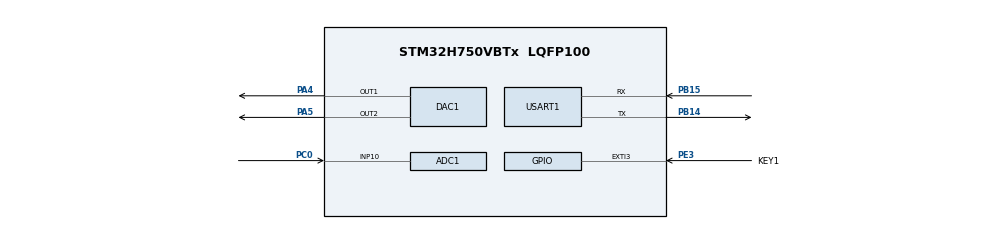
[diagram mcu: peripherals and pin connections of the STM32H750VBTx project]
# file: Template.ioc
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ADC1.Channel-0\#ChannelRegularConversion=ADC_CHANNEL_10
ADC1.ConversionDataManagement=ADC_CONVERSIONDATA_DMA_CIRCULAR
ADC1.ExternalTrigConv=ADC_EXTERNALTRIG_T15_TRGO
ADC1.NbrOfConversionFlag=1
ADC1.OffsetNumber-0\#ChannelRegularConversion=ADC_OFFSET_NONE
ADC1.OffsetSignedSaturation-0\#ChannelRegularConversion=DISABLE
ADC1.Rank-0\#ChannelRegularConversion=1
ADC1.SamplingTime-0\#ChannelRegularConversion=ADC_SAMPLETIME_1CYCLE_5
ADC1.master=1
CORTEX_M7.AccessPermission-Cortex_Memory_Protection_Unit_Region0_Settings=MPU_REGION_FULL_ACCESS
CORTEX_M7.AccessPermission-Cortex_Memory_Protection_Unit_Region1_Settings=MPU_REGION_FULL_ACCESS
CORTEX_M7.AccessPermission-Cortex_Memory_Protection_Unit_Region2_Settings=MPU_REGION_FULL_ACCESS
CORTEX_M7.AccessPermission-Cortex_Memory_Protection_Unit_Region3_Settings=MPU_REGION_FULL_ACCESS
CORTEX_M7.AccessPermission-Cortex_Memory_Protection_Unit_Region4_Settings=MPU_REGION_FULL_ACCESS
CORTEX_M7.BaseAddress-Cortex_Memory_Protection_Unit_Region0_Settings=0x24000000
CORTEX_M7.BaseAddress-Cortex_Memory_Protection_Unit_Region1_Settings=0x30000000
CORTEX_M7.BaseAddress-Cortex_Memory_Protection_Unit_Region2_Settings=0x30020000
CORTEX_M7.BaseAddress-Cortex_Memory_Protection_Unit_Region3_Settings=0x30040000
CORTEX_M7.BaseAddress-Cortex_Memory_Protection_Unit_Region4_Settings=0x38000000
CORTEX_M7.CPU_DCache=Enabled
CORTEX_M7.CPU_ICache=Enabled
CORTEX_M7.Enable-Cortex_Memory_Protection_Unit_Region0_Settings=MPU_REGION_ENABLE
CORTEX_M7.Enable-Cortex_Memory_Protection_Unit_Region1_Settings=MPU_REGION_ENABLE
CORTEX_M7.Enable-Cortex_Memory_Protection_Unit_Region2_Settings=MPU_REGION_ENABLE
CORTEX_M7.Enable-Cortex_Memory_Protection_Unit_Region3_Settings=MPU_REGION_ENABLE
CORTEX_M7.Enable-Cortex_Memory_Protection_Unit_Region4_Settings=MPU_REGION_ENABLE
CORTEX_M7.IsBufferable-Cortex_Memory_Protection_Unit_Region0_Settings=MPU_ACCESS_BUFFERABLE
CORTEX_M7.IsCacheable-Cortex_Memory_Protection_Unit_Region0_Settings=MPU_ACCESS_CACHEABLE
CORTEX_M7.MPU_Control=MPU_PRIVILEGED_DEFAULT
CORTEX_M7.Size-Cortex_Memory_Protection_Unit_Region0_Settings=MPU_REGION_SIZE_512KB
CORTEX_M7.Size-Cortex_Memory_Protection_Unit_Region1_Settings=MPU_REGION_SIZE_128KB
CORTEX_M7.Size-Cortex_Memory_Protection_Unit_Region2_Settings=MPU_REGION_SIZE_128KB
CORTEX_M7.Size-Cortex_Memory_Protection_Unit_Region3_Settings=MPU_REGION_SIZE_32KB
CORTEX_M7.Size-Cortex_Memory_Protection_Unit_Region4_Settings=MPU_REGION_SIZE_64KB
CORTEX_M7.TypeExtField-Cortex_Memory_Protection_Unit_Region0_Settings=MPU_TEX_LEVEL1
CORTEX_M7.TypeExtField-Cortex_Memory_Protection_Unit_Region1_Settings=MPU_TEX_LEVEL1
CORTEX_M7.TypeExtField-Cortex_Memory_Protection_Unit_Region2_Settings=MPU_TEX_LEVEL1
CORTEX_M7.TypeExtField-Cortex_Memory_Protection_Unit_Region3_Settings=MPU_TEX_LEVEL1
CORTEX_M7.TypeExtField-Cortex_Memory_Protection_Unit_Region4_Settings=MPU_TEX_LEVEL1
DAC1.DAC1_OutputBuffer-DAC_OUT1=DAC_OUTPUTBUFFER_DISABLE
DAC1.DAC2_OutputBuffer-DAC_OUT2=DAC_OUTPUTBUFFER_DISABLE
DAC1.DAC_Channel-DAC_OUT1=DAC_CHANNEL_1
DAC1.DAC_Channel-DAC_OUT2=DAC_CHANNEL_2
DAC1.DAC_Trigger-DAC_OUT1=DAC_TRIGGER_T1_TRGO
DAC1.DAC_Trigger-DAC_OUT2=DAC_TRIGGER_T4_TRGO
DAC1.DAC_UserTrimming-DAC_OUT1=DAC_TRIMMING_FACTORY
Dma.ADC1.0.Direction=DMA_PERIPH_TO_MEMORY
Dma.ADC1.0.EventEnable=DISABLE
Dma.ADC1.0.FIFOMode=DMA_FIFOMODE_DISABLE
Dma.ADC1.0.Instance=DMA1_Stream0
Dma.ADC1.0.MemDataAlignment=DMA_MDATAALIGN_HALFWORD
Dma.ADC1.0.MemInc=DMA_MINC_ENABLE
Dma.ADC1.0.Mode=DMA_NORMAL
Dma.ADC1.0.PeriphDataAlignment=DMA_PDATAALIGN_HALFWORD
Dma.ADC1.0.PeriphInc=DMA_PINC_DISABLE
Dma.ADC1.0.Polarity=HAL_DMAMUX_REQ_GEN_RISING
Dma.ADC1.0.Priority=DMA_PRIORITY_LOW
Dma.ADC1.0.RequestNumber=1
Dma.ADC1.0.SignalID=NONE
Dma.ADC1.0.SyncEnable=DISABLE
Dma.ADC1.0.SyncPolarity=HAL_DMAMUX_SYNC_NO_EVENT
Dma.ADC1.0.SyncRequestNumber=1
Dma.ADC1.0.SyncSignalID=NONE
Dma.DAC1_CH1.1.Direction=DMA_MEMORY_TO_PERIPH
Dma.DAC1_CH1.1.EventEnable=DISABLE
Dma.DAC1_CH1.1.FIFOMode=DMA_FIFOMODE_DISABLE
Dma.DAC1_CH1.1.Instance=DMA1_Stream1
Dma.DAC1_CH1.1.MemDataAlignment=DMA_MDATAALIGN_HALFWORD
Dma.DAC1_CH1.1.MemInc=DMA_MINC_ENABLE
Dma.DAC1_CH1.1.Mode=DMA_CIRCULAR
Dma.DAC1_CH1.1.PeriphDataAlignment=DMA_PDATAALIGN_HALFWORD
Dma.DAC1_CH1.1.PeriphInc=DMA_PINC_DISABLE
Dma.DAC1_CH1.1.Polarity=HAL_DMAMUX_REQ_GEN_RISING
Dma.DAC1_CH1.1.Priority=DMA_PRIORITY_LOW
Dma.DAC1_CH1.1.RequestNumber=1
Dma.DAC1_CH1.1.SignalID=NONE
Dma.DAC1_CH1.1.SyncEnable=DISABLE
Dma.DAC1_CH1.1.SyncPolarity=HAL_DMAMUX_SYNC_NO_EVENT
Dma.DAC1_CH1.1.SyncRequestNumber=1
Dma.DAC1_CH1.1.SyncSignalID=NONE
Dma.DAC1_CH2.2.Direction=DMA_MEMORY_TO_PERIPH
Dma.DAC1_CH2.2.EventEnable=DISABLE
Dma.DAC1_CH2.2.FIFOMode=DMA_FIFOMODE_DISABLE
Dma.DAC1_CH2.2.Instance=DMA1_Stream2
Dma.DAC1_CH2.2.MemDataAlignment=DMA_MDATAALIGN_HALFWORD
Dma.DAC1_CH2.2.MemInc=DMA_MINC_ENABLE
Dma.DAC1_CH2.2.Mode=DMA_CIRCULAR
Dma.DAC1_CH2.2.PeriphDataAlignment=DMA_PDATAALIGN_HALFWORD
Dma.DAC1_CH2.2.PeriphInc=DMA_PINC_DISABLE
Dma.DAC1_CH2.2.Polarity=HAL_DMAMUX_REQ_GEN_RISING
Dma.DAC1_CH2.2.Priority=DMA_PRIORITY_LOW
Dma.DAC1_CH2.2.RequestNumber=1
Dma.DAC1_CH2.2.SignalID=NONE
Dma.DAC1_CH2.2.SyncEnable=DISABLE
Dma.DAC1_CH2.2.SyncPolarity=HAL_DMAMUX_SYNC_NO_EVENT
Dma.DAC1_CH2.2.SyncRequestNumber=1
Dma.DAC1_CH2.2.SyncSignalID=NONE
Dma.Request0=ADC1
Dma.Request1=DAC1_CH1
Dma.Request2=DAC1_CH2
Mcu.Family=STM32H7
Mcu.Name=STM32H750VBTx
Mcu.Package=LQFP100
NVIC.DMA1_Stream0_IRQn=true\:0\:0\:false\:false\:true\:false\:true\:true
NVIC.DMA1_Stream1_IRQn=true\:0\:0\:false\:false\:true\:false\:true\:true
NVIC.DMA1_Stream2_IRQn=true\:0\:0\:false\:false\:true\:false\:true\:true
NVIC.EXTI3_IRQn=true\:0\:0\:false\:false\:true\:true\:true\:true
NVIC.PriorityGroup=NVIC_PRIORITYGROUP_4
PA13\ (JTMS/SWDIO).Mode=Serial_Wire
PA13\ (JTMS/SWDIO).Signal=DEBUG_JTMS-SWDIO
PA14\ (JTCK/SWCLK).Mode=Serial_Wire
PA14\ (JTCK/SWCLK).Signal=DEBUG_JTCK-SWCLK
PA4.Signal=COMP_DAC11_group
PA5.Signal=COMP_DAC12_group
PB14.Mode=Asynchronous
PB14.Signal=USART1_TX
PB15.Mode=Asynchronous
PB15.Signal=USART1_RX
PC0.Signal=ADCx_INP10
PE3.GPIO_Label=KEY1
PE3.GPIO_ModeDefaultEXTI=GPIO_MODE_IT_FALLING
PE3.GPIO_PuPd=GPIO_PULLUP
PE3.Signal=GPXTI3
PH0-OSC_IN\ (PH0).Mode=HSE-External-Oscillator
PH0-OSC_IN\ (PH0).Signal=RCC_OSC_IN
PH1-OSC_OUT\ (PH1).Mode=HSE-External-Oscillator
PH1-OSC_OUT\ (PH1).Signal=RCC_OSC_OUT
ProjectManager.HeapSize=0x200
ProjectManager.StackSize=0x7400
ProjectManager.TargetToolchain=MDK-ARM V5.32
RCC.ADCFreq_Value=72000000
RCC.APB1Freq_Value=120000000
RCC.APB2Freq_Value=120000000
RCC.APB3Freq_Value=120000000
RCC.APB4Freq_Value=120000000
RCC.CortexFreq_Value=480000000
RCC.D1PPRE=RCC_APB3_DIV2
RCC.D2PPRE1=RCC_APB1_DIV2
RCC.D2PPRE2=RCC_APB2_DIV2
RCC.D3PPRE=RCC_APB4_DIV2
RCC.DIVM1=5
RCC.DIVM2=25
RCC.DIVN1=192
RCC.DIVN2=360
RCC.DIVP2=5
RCC.HCLKFreq_Value=240000000
RCC.HPRE=RCC_HCLK_DIV2
RCC.PLLSourceVirtual=RCC_PLLSOURCE_HSE
RCC.ProductRev=revV
RCC.SYSCLKFreq_VALUE=480000000
RCC.SYSCLKSource=RCC_SYSCLKSOURCE_PLLCLK
RCC.USBFreq_Value=480000000
SH.ADCx_INP10.0=ADC1_INP10,IN10-Single-Ended
SH.COMP_DAC11_group.0=DAC1_OUT1,DAC_OUT1
SH.COMP_DAC12_group.0=DAC1_OUT2,DAC_OUT2
TIM1.Period=240-1
TIM1.TIM_MasterOutputTrigger=TIM_TRGO_UPDATE
TIM15.Period=240-1
TIM15.TIM_MasterOutputTrigger=TIM_TRGO_UPDATE
TIM4.AutoReloadPreload=TIM_AUTORELOAD_PRELOAD_ENABLE
TIM4.Period=240-1
TIM4.TIM_MasterOutputTrigger=TIM_TRGO_UPDATE
TIM7.Prescaler=239
USART1.VirtualMode-Asynchronous=VM_ASYNC
VP_TIM15_VS_ClockSourceINT.Mode=Internal
VP_TIM1_VS_ClockSourceINT.Mode=Internal
VP_TIM4_VS_ClockSourceINT.Mode=Internal
VP_TIM7_VS_ClockSourceINT.Mode=Enable_Timer
board=custom

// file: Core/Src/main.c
/* USER CODE BEGIN Header */
/**
  ******************************************************************************
  * @file           : main.c
  * @brief          : Main program body
  ******************************************************************************
  * @attention
  *
  * Copyright (c) 2023 STMicroelectronics.
  * All rights reserved.
  *
  * This software is licensed under terms that can be found in the LICENSE file
  * in the root directory of this software component.
  * If no LICENSE file comes with this software, it is provided AS-IS.
  *
  ******************************************************************************
  */
/* USER CODE END Header */
#include "main.h"
#include "adc.h"
#include "dac.h"
#include "dma.h"
#include "tim.h"
#include "usart.h"
#include "gpio.h"

/* USER CODE BEGIN PTD */
ALIGN_32BYTES (uint16_t adc1_data[DFT_LENGTH]) 	__attribute__((section(".ARM.__at_0x30000000")));
__IO uint8_t AdcConvEnd = 0;//表示adc采集完成

uint8_t mode_flag = 0;			//0自校正，1手调节
uint8_t restart_flag = 0;		//重新分离

// 信号频率	索引
uint8_t fre[2];
// 信号种类	0正弦 1三角
uint8_t wave_type[2];
//	DAC输出数据
ALIGN_32BYTES (uint16_t data_A[200]) 	__attribute__((section(".ARM.__at_0x38000000")));
ALIGN_32BYTES (uint16_t data_B[200]) 	__attribute__((section(".ARM.__at_0x38004000")));
//	信号相差
double pos_angle_A;
double pos_angle_B;
//时差
double delayA;
//	延时
uint32_t delayT_A;
uint32_t delayT_B;
//	输入移相0-180
uint8_t change_pha = 0;
/* USER CODE END PTD */

/* USER CODE BEGIN PM */

// 标准频率sin与cos表
uint16_t DAC_SIN[200 * 19] =
    // 第一行是20K -> 1s 10K
    { // DAC正弦缓冲区,每行 200点。第一行有2个正弦波，第三行有4个……第19行有20个
        2142, 2236, 2329, 2421, 2512, 2600, 2687, 2771, 2852, 2930, 3004, 3075, 3141, 3204, 3262, 3314, 3362, 3405, 3443, 3475, 3501, 3521, 3536, 3545, 3548, 3545, 3536, 3521, 3501, 3475, 3443, 3405, 3362, 3314, 3262, 3204, 3141, 3075, 3004, 2930, 2852, 2771, 2687, 2600, 2512, 2421, 2329, 2236, 2142, 2048, 1954, 1860, 1767, 1675, 1584, 1496, 1409, 1325, 1244, 1166, 1092, 1021, 955, 892, 834, 782, 734, 691, 653, 621, 595, 575, 560, 551, 548, 551, 560, 575, 595, 621, 653, 691, 734, 782, 834, 892, 955, 1021, 1092, 1166, 1244, 1325, 1409, 1496, 1584, 1675, 1767, 1860, 1954, 2048, 2142, 2236, 2329, 2421, 2512, 2600, 2687, 2771, 2852, 2930, 3004, 3075, 3141, 3204, 3262, 3314, 3362, 3405, 3443, 3475, 3501, 3521, 3536, 3545, 3548, 3545, 3536, 3521, 3501, 3475, 3443, 3405, 3362, 3314, 3262, 3204, 3141, 3075, 3004, 2930, 2852, 2771, 2687, 2600, 2512, 2421, 2329, 2236, 2142, 2048, 1954, 1860, 1767, 1675, 1584, 1496, 1409, 1325, 1244, 1166, 1092, 1021, 955, 892, 834, 782, 734, 691, 653, 621, 595, 575, 560, 551, 548, 551, 560, 575, 595, 621, 653, 691, 734, 782, 834, 892, 955, 1021, 1092, 1166, 1244, 1325, 1409, 1496, 1584, 1675, 1767, 1860, 1954, 2048,
        2189, 2329, 2466, 2600, 2729, 2852, 2967, 3075, 3173, 3262, 3339, 3405, 3459, 3501, 3530, 3545, 3547, 3536, 3512, 3475, 3425, 3362, 3289, 3204, 3109, 3004, 2891, 2771, 2644, 2512, 2375, 2236, 2095, 1954, 1813, 1675, 1540, 1409, 1284, 1166, 1056, 955, 863, 782, 711, 653, 608, 575, 555, 548, 555, 575, 608, 653, 711, 782, 863, 955, 1056, 1166, 1284, 1409, 1540, 1675, 1813, 1954, 2095, 2236, 2375, 2512, 2644, 2771, 2891, 3004, 3109, 3204, 3289, 3362, 3425, 3475, 3512, 3536, 3547, 3545, 3530, 3501, 3459, 3405, 3339, 3262, 3173, 3075, 2967, 2852, 2729, 2600, 2466, 2329, 2189, 2048, 1907, 1767, 1630, 1496, 1367, 1244, 1129, 1021, 923, 834, 757, 691, 637, 595, 566, 551, 549, 560, 584, 621, 671, 734, 807, 892, 987, 1092, 1205, 1325, 1452, 1584, 1721, 1860, 2001, 2142, 2283, 2421, 2556, 2687, 2812, 2930, 3040, 3141, 3233, 3314, 3385, 3443, 3488, 3521, 3541, 3548, 3541, 3521, 3488, 3443, 3385, 3314, 3233, 3141, 3040, 2930, 2812, 2687, 2556, 2421, 2283, 2142, 2001, 1860, 1721, 1584, 1452, 1325, 1205, 1092, 987, 892, 807, 734, 671, 621, 584, 560, 549, 551, 566, 595, 637, 691, 757, 834, 923, 1021, 1129, 1244, 1367, 1496, 1630, 1767, 1907, 2048,
        2236, 2421, 2600, 2771, 2930, 3075, 3204, 3314, 3405, 3475, 3521, 3545, 3545, 3521, 3475, 3405, 3314, 3204, 3075, 2930, 2771, 2600, 2421, 2236, 2048, 1860, 1675, 1496, 1325, 1166, 1021, 892, 782, 691, 621, 575, 551, 551, 575, 621, 691, 782, 892, 1021, 1166, 1325, 1496, 1675, 1860, 2048, 2236, 2421, 2600, 2771, 2930, 3075, 3204, 3314, 3405, 3475, 3521, 3545, 3545, 3521, 3475, 3405, 3314, 3204, 3075, 2930, 2771, 2600, 2421, 2236, 2048, 1860, 1675, 1496, 1325, 1166, 1021, 892, 782, 691, 621, 575, 551, 551, 575, 621, 691, 782, 892, 1021, 1166, 1325, 1496, 1675, 1860, 2048, 2236, 2421, 2600, 2771, 2930, 3075, 3204, 3314, 3405, 3475, 3521, 3545, 3545, 3521, 3475, 3405, 3314, 3204, 3075, 2930, 2771, 2600, 2421, 2236, 2048, 1860, 1675, 1496, 1325, 1166, 1021, 892, 782, 691, 621, 575, 551, 551, 575, 621, 691, 782, 892, 1021, 1166, 1325, 1496, 1675, 1860, 2048, 2236, 2421, 2600, 2771, 2930, 3075, 3204, 3314, 3405, 3475, 3521, 3545, 3545, 3521, 3475, 3405, 3314, 3204, 3075, 2930, 2771, 2600, 2421, 2236, 2048, 1860, 1675, 1496, 1325, 1166, 1021, 892, 782, 691, 621, 575, 551, 551, 575, 621, 691, 782, 892, 1021, 1166, 1325, 1496, 1675, 1860, 2048,
        2283, 2512, 2729, 2930, 3109, 3262, 3385, 3475, 3530, 3548, 3530, 3475, 3385, 3262, 3109, 2930, 2729, 2512, 2283, 2048, 1813, 1584, 1367, 1166, 987, 834, 711, 621, 566, 548, 566, 621, 711, 834, 987, 1166, 1367, 1584, 1813, 2048, 2283, 2512, 2729, 2930, 3109, 3262, 3385, 3475, 3530, 3548, 3530, 3475, 3385, 3262, 3109, 2930, 2729, 2512, 2283, 2048, 1813, 1584, 1367, 1166, 987, 834, 711, 621, 566, 548, 566, 621, 711, 834, 987, 1166, 1367, 1584, 1813, 2048, 2283, 2512, 2729, 2930, 3109, 3262, 3385, 3475, 3530, 3548, 3530, 3475, 3385, 3262, 3109, 2930, 2729, 2512, 2283, 2048, 1813, 1584, 1367, 1166, 987, 834, 711, 621, 566, 548, 566, 621, 711, 834, 987, 1166, 1367, 1584, 1813, 2048, 2283, 2512, 2729, 2930, 3109, 3262, 3385, 3475, 3530, 3548, 3530, 3475, 3385, 3262, 3109, 2930, 2729, 2512, 2283, 2048, 1813, 1584, 1367, 1166, 987, 834, 711, 621, 566, 548, 566, 621, 711, 834, 987, 1166, 1367, 1584, 1813, 2048, 2283, 2512, 2729, 2930, 3109, 3262, 3385, 3475, 3530, 3548, 3530, 3475, 3385, 3262, 3109, 2930, 2729, 2512, 2283, 2048, 1813, 1584, 1367, 1166, 987, 834, 711, 621, 566, 548, 566, 621, 711, 834, 987, 1166, 1367, 1584, 1813, 2048,
        2329, 2600, 2852, 3075, 3262, 3405, 3501, 3545, 3536, 3475, 3362, 3204, 3004, 2771, 2512, 2236, 1954, 1675, 1409, 1166, 955, 782, 653, 575, 548, 575, 653, 782, 955, 1166, 1409, 1675, 1954, 2236, 2512, 2771, 3004, 3204, 3362, 3475, 3536, 3545, 3501, 3405, 3262, 3075, 2852, 2600, 2329, 2048, 1767, 1496, 1244, 1021, 834, 691, 595, 551, 560, 621, 734, 892, 1092, 1325, 1584, 1860, 2142, 2421, 2687, 2930, 3141, 3314, 3443, 3521, 3548, 3521, 3443, 3314, 3141, 2930, 2687, 2421, 2142, 1860, 1584, 1325, 1092, 892, 734, 621, 560, 551, 595, 691, 834, 1021, 1244, 1496, 1767, 2048, 2329, 2600, 2852, 3075, 3262, 3405, 3501, 3545, 3536, 3475, 3362, 3204, 3004, 2771, 2512, 2236, 1954, 1675, 1409, 1166, 955, 782, 653, 575, 548, 575, 653, 782, 955, 1166, 1409, 1675, 1954, 2236, 2512, 2771, 3004, 3204, 3362, 3475, 3536, 3545, 3501, 3405, 3262, 3075, 2852, 2600, 2329, 2048, 1767, 1496, 1244, 1021, 834, 691, 595, 551, 560, 621, 734, 892, 1092, 1325, 1584, 1860, 2142, 2421, 2687, 2930, 3141, 3314, 3443, 3521, 3548, 3521, 3443, 3314, 3141, 2930, 2687, 2421, 2142, 1860, 1584, 1325, 1092, 892, 734, 621, 560, 551, 595, 691, 834, 1021, 1244, 1496, 1767, 2048,
        2375, 2687, 2967, 3204, 3385, 3501, 3547, 3521, 3425, 3262, 3040, 2771, 2466, 2142, 1813, 1496, 1205, 955, 757, 621, 555, 560, 637, 782, 987, 1244, 1540, 1860, 2189, 2512, 2812, 3075, 3289, 3443, 3530, 3545, 3488, 3362, 3173, 2930, 2644, 2329, 2001, 1675, 1367, 1092, 863, 691, 584, 548, 584, 691, 863, 1092, 1367, 1675, 2001, 2329, 2644, 2930, 3173, 3362, 3488, 3545, 3530, 3443, 3289, 3075, 2812, 2512, 2189, 1860, 1540, 1244, 987, 782, 637, 560, 555, 621, 757, 955, 1205, 1496, 1813, 2142, 2466, 2771, 3040, 3262, 3425, 3521, 3547, 3501, 3385, 3204, 2967, 2687, 2375, 2048, 1721, 1409, 1129, 892, 711, 595, 549, 575, 671, 834, 1056, 1325, 1630, 1954, 2283, 2600, 2891, 3141, 3339, 3475, 3541, 3536, 3459, 3314, 3109, 2852, 2556, 2236, 1907, 1584, 1284, 1021, 807, 653, 566, 551, 608, 734, 923, 1166, 1452, 1767, 2095, 2421, 2729, 3004, 3233, 3405, 3512, 3548, 3512, 3405, 3233, 3004, 2729, 2421, 2095, 1767, 1452, 1166, 923, 734, 608, 551, 566, 653, 807, 1021, 1284, 1584, 1907, 2236, 2556, 2852, 3109, 3314, 3459, 3536, 3541, 3475, 3339, 3141, 2891, 2600, 2283, 1954, 1630, 1325, 1056, 834, 671, 575, 549, 595, 711, 892, 1129, 1409, 1721, 2048,
        2421, 2771, 3075, 3314, 3475, 3545, 3521, 3405, 3204, 2930, 2600, 2236, 1860, 1496, 1166, 892, 691, 575, 551, 621, 782, 1021, 1325, 1675, 2048, 2421, 2771, 3075, 3314, 3475, 3545, 3521, 3405, 3204, 2930, 2600, 2236, 1860, 1496, 1166, 892, 691, 575, 551, 621, 782, 1021, 1325, 1675, 2048, 2421, 2771, 3075, 3314, 3475, 3545, 3521, 3405, 3204, 2930, 2600, 2236, 1860, 1496, 1166, 892, 691, 575, 551, 621, 782, 1021, 1325, 1675, 2048, 2421, 2771, 3075, 3314, 3475, 3545, 3521, 3405, 3204, 2930, 2600, 2236, 1860, 1496, 1166, 892, 691, 575, 551, 621, 782, 1021, 1325, 1675, 2048, 2421, 2771, 3075, 3314, 3475, 3545, 3521, 3405, 3204, 2930, 2600, 2236, 1860, 1496, 1166, 892, 691, 575, 551, 621, 782, 1021, 1325, 1675, 2048, 2421, 2771, 3075, 3314, 3475, 3545, 3521, 3405, 3204, 2930, 2600, 2236, 1860, 1496, 1166, 892, 691, 575, 551, 621, 782, 1021, 1325, 1675, 2048, 2421, 2771, 3075, 3314, 3475, 3545, 3521, 3405, 3204, 2930, 2600, 2236, 1860, 1496, 1166, 892, 691, 575, 551, 621, 782, 1021, 1325, 1675, 2048, 2421, 2771, 3075, 3314, 3475, 3545, 3521, 3405, 3204, 2930, 2600, 2236, 1860, 1496, 1166, 892, 691, 575, 551, 621, 782, 1021, 1325, 1675, 2048,
        2466, 2852, 3173, 3405, 3530, 3536, 3425, 3204, 2891, 2512, 2095, 1675, 1284, 955, 711, 575, 555, 653, 863, 1166, 1540, 1954, 2375, 2771, 3109, 3362, 3512, 3545, 3459, 3262, 2967, 2600, 2189, 1767, 1367, 1021, 757, 595, 549, 621, 807, 1092, 1452, 1860, 2283, 2687, 3040, 3314, 3488, 3548, 3488, 3314, 3040, 2687, 2283, 1860, 1452, 1092, 807, 621, 549, 595, 757, 1021, 1367, 1767, 2189, 2600, 2967, 3262, 3459, 3545, 3512, 3362, 3109, 2771, 2375, 1954, 1540, 1166, 863, 653, 555, 575, 711, 955, 1284, 1675, 2095, 2512, 2891, 3204, 3425, 3536, 3530, 3405, 3173, 2852, 2466, 2048, 1630, 1244, 923, 691, 566, 560, 671, 892, 1205, 1584, 2001, 2421, 2812, 3141, 3385, 3521, 3541, 3443, 3233, 2930, 2556, 2142, 1721, 1325, 987, 734, 584, 551, 637, 834, 1129, 1496, 1907, 2329, 2729, 3075, 3339, 3501, 3547, 3475, 3289, 3004, 2644, 2236, 1813, 1409, 1056, 782, 608, 548, 608, 782, 1056, 1409, 1813, 2236, 2644, 3004, 3289, 3475, 3547, 3501, 3339, 3075, 2729, 2329, 1907, 1496, 1129, 834, 637, 551, 584, 734, 987, 1325, 1721, 2142, 2556, 2930, 3233, 3443, 3541, 3521, 3385, 3141, 2812, 2421, 2001, 1584, 1205, 892, 671, 560, 566, 691, 923, 1244, 1630, 2048,
        2512, 2930, 3262, 3475, 3548, 3475, 3262, 2930, 2512, 2048, 1584, 1166, 834, 621, 548, 621, 834, 1166, 1584, 2048, 2512, 2930, 3262, 3475, 3548, 3475, 3262, 2930, 2512, 2048, 1584, 1166, 834, 621, 548, 621, 834, 1166, 1584, 2048, 2512, 2930, 3262, 3475, 3548, 3475, 3262, 2930, 2512, 2048, 1584, 1166, 834, 621, 548, 621, 834, 1166, 1584, 2048, 2512, 2930, 3262, 3475, 3548, 3475, 3262, 2930, 2512, 2048, 1584, 1166, 834, 621, 548, 621, 834, 1166, 1584, 2048, 2512, 2930, 3262, 3475, 3548, 3475, 3262, 2930, 2512, 2048, 1584, 1166, 834, 621, 548, 621, 834, 1166, 1584, 2048, 2512, 2930, 3262, 3475, 3548, 3475, 3262, 2930, 2512, 2048, 1584, 1166, 834, 621, 548, 621, 834, 1166, 1584, 2048, 2512, 2930, 3262, 3475, 3548, 3475, 3262, 2930, 2512, 2048, 1584, 1166, 834, 621, 548, 621, 834, 1166, 1584, 2048, 2512, 2930, 3262, 3475, 3548, 3475, 3262, 2930, 2512, 2048, 1584, 1166, 834, 621, 548, 621, 834, 1166, 1584, 2048, 2512, 2930, 3262, 3475, 3548, 3475, 3262, 2930, 2512, 2048, 1584, 1166, 834, 621, 548, 621, 834, 1166, 1584, 2048, 2512, 2930, 3262, 3475, 3548, 3475, 3262, 2930, 2512, 2048, 1584, 1166, 834, 621, 548, 621, 834, 1166, 1584, 2048,
        2556, 3004, 3339, 3521, 3530, 3362, 3040, 2600, 2095, 1584, 1129, 782, 584, 560, 711, 1021, 1452, 1954, 2466, 2930, 3289, 3501, 3541, 3405, 3109, 2687, 2189, 1675, 1205, 834, 608, 551, 671, 955, 1367, 1860, 2375, 2852, 3233, 3475, 3547, 3443, 3173, 2771, 2283, 1767, 1284, 892, 637, 548, 637, 892, 1284, 1767, 2283, 2771, 3173, 3443, 3547, 3475, 3233, 2852, 2375, 1860, 1367, 955, 671, 551, 608, 834, 1205, 1675, 2189, 2687, 3109, 3405, 3541, 3501, 3289, 2930, 2466, 1954, 1452, 1021, 711, 560, 584, 782, 1129, 1584, 2095, 2600, 3040, 3362, 3530, 3521, 3339, 3004, 2556, 2048, 1540, 1092, 757, 575, 566, 734, 1056, 1496, 2001, 2512, 2967, 3314, 3512, 3536, 3385, 3075, 2644, 2142, 1630, 1166, 807, 595, 555, 691, 987, 1409, 1907, 2421, 2891, 3262, 3488, 3545, 3425, 3141, 2729, 2236, 1721, 1244, 863, 621, 549, 653, 923, 1325, 1813, 2329, 2812, 3204, 3459, 3548, 3459, 3204, 2812, 2329, 1813, 1325, 923, 653, 549, 621, 863, 1244, 1721, 2236, 2729, 3141, 3425, 3545, 3488, 3262, 2891, 2421, 1907, 1409, 987, 691, 555, 595, 807, 1166, 1630, 2142, 2644, 3075, 3385, 3536, 3512, 3314, 2967, 2512, 2001, 1496, 1056, 734, 566, 575, 757, 1092, 1540, 2048,
        2600, 3075, 3405, 3545, 3475, 3204, 2771, 2236, 1675, 1166, 782, 575, 575, 782, 1166, 1675, 2236, 2771, 3204, 3475, 3545, 3405, 3075, 2600, 2048, 1496, 1021, 691, 551, 621, 892, 1325, 1860, 2421, 2930, 3314, 3521, 3521, 3314, 2930, 2421, 1860, 1325, 892, 621, 551, 691, 1021, 1496, 2048, 2600, 3075, 3405, 3545, 3475, 3204, 2771, 2236, 1675, 1166, 782, 575, 575, 782, 1166, 1675, 2236, 2771, 3204, 3475, 3545, 3405, 3075, 2600, 2048, 1496, 1021, 691, 551, 621, 892, 1325, 1860, 2421, 2930, 3314, 3521, 3521, 3314, 2930, 2421, 1860, 1325, 892, 621, 551, 691, 1021, 1496, 2048, 2600, 3075, 3405, 3545, 3475, 3204, 2771, 2236, 1675, 1166, 782, 575, 575, 782, 1166, 1675, 2236, 2771, 3204, 3475, 3545, 3405, 3075, 2600, 2048, 1496, 1021, 691, 551, 621, 892, 1325, 1860, 2421, 2930, 3314, 3521, 3521, 3314, 2930, 2421, 1860, 1325, 892, 621, 551, 691, 1021, 1496, 2048, 2600, 3075, 3405, 3545, 3475, 3204, 2771, 2236, 1675, 1166, 782, 575, 575, 782, 1166, 1675, 2236, 2771, 3204, 3475, 3545, 3405, 3075, 2600, 2048, 1496, 1021, 691, 551, 621, 892, 1325, 1860, 2421, 2930, 3314, 3521, 3521, 3314, 2930, 2421, 1860, 1325, 892, 621, 551, 691, 1021, 1496, 2048,
        2644, 3141, 3459, 3545, 3385, 3004, 2466, 1860, 1284, 834, 584, 575, 807, 1244, 1813, 2421, 2967, 3362, 3541, 3475, 3173, 2687, 2095, 1496, 987, 653, 549, 691, 1056, 1584, 2189, 2771, 3233, 3501, 3530, 3314, 2891, 2329, 1721, 1166, 757, 560, 608, 892, 1367, 1954, 2556, 3075, 3425, 3548, 3425, 3075, 2556, 1954, 1367, 892, 608, 560, 757, 1166, 1721, 2329, 2891, 3314, 3530, 3501, 3233, 2771, 2189, 1584, 1056, 691, 549, 653, 987, 1496, 2095, 2687, 3173, 3475, 3541, 3362, 2967, 2421, 1813, 1244, 807, 575, 584, 834, 1284, 1860, 2466, 3004, 3385, 3545, 3459, 3141, 2644, 2048, 1452, 955, 637, 551, 711, 1092, 1630, 2236, 2812, 3262, 3512, 3521, 3289, 2852, 2283, 1675, 1129, 734, 555, 621, 923, 1409, 2001, 2600, 3109, 3443, 3547, 3405, 3040, 2512, 1907, 1325, 863, 595, 566, 782, 1205, 1767, 2375, 2930, 3339, 3536, 3488, 3204, 2729, 2142, 1540, 1021, 671, 548, 671, 1021, 1540, 2142, 2729, 3204, 3488, 3536, 3339, 2930, 2375, 1767, 1205, 782, 566, 595, 863, 1325, 1907, 2512, 3040, 3405, 3547, 3443, 3109, 2600, 2001, 1409, 923, 621, 555, 734, 1129, 1675, 2283, 2852, 3289, 3521, 3512, 3262, 2812, 2236, 1630, 1092, 711, 551, 637, 955, 1452, 2048,
        2687, 3204, 3501, 3521, 3262, 2771, 2142, 1496, 955, 621, 560, 782, 1244, 1860, 2512, 3075, 3443, 3545, 3362, 2930, 2329, 1675, 1092, 691, 548, 691, 1092, 1675, 2329, 2930, 3362, 3545, 3443, 3075, 2512, 1860, 1244, 782, 560, 621, 955, 1496, 2142, 2771, 3262, 3521, 3501, 3204, 2687, 2048, 1409, 892, 595, 575, 834, 1325, 1954, 2600, 3141, 3475, 3536, 3314, 2852, 2236, 1584, 1021, 653, 551, 734, 1166, 1767, 2421, 3004, 3405, 3548, 3405, 3004, 2421, 1767, 1166, 734, 551, 653, 1021, 1584, 2236, 2852, 3314, 3536, 3475, 3141, 2600, 1954, 1325, 834, 575, 595, 892, 1409, 2048, 2687, 3204, 3501, 3521, 3262, 2771, 2142, 1496, 955, 621, 560, 782, 1244, 1860, 2512, 3075, 3443, 3545, 3362, 2930, 2329, 1675, 1092, 691, 548, 691, 1092, 1675, 2329, 2930, 3362, 3545, 3443, 3075, 2512, 1860, 1244, 782, 560, 621, 955, 1496, 2142, 2771, 3262, 3521, 3501, 3204, 2687, 2048, 1409, 892, 595, 575, 834, 1325, 1954, 2600, 3141, 3475, 3536, 3314, 2852, 2236, 1584, 1021, 653, 551, 734, 1166, 1767, 2421, 3004, 3405, 3548, 3405, 3004, 2421, 1767, 1166, 734, 551, 653, 1021, 1584, 2236, 2852, 3314, 3536, 3475, 3141, 2600, 1954, 1325, 834, 575, 595, 892, 1409, 2048,
        2729, 3262, 3530, 3475, 3109, 2512, 1813, 1166, 711, 548, 711, 1166, 1813, 2512, 3109, 3475, 3530, 3262, 2729, 2048, 1367, 834, 566, 621, 987, 1584, 2283, 2930, 3385, 3548, 3385, 2930, 2283, 1584, 987, 621, 566, 834, 1367, 2048, 2729, 3262, 3530, 3475, 3109, 2512, 1813, 1166, 711, 548, 711, 1166, 1813, 2512, 3109, 3475, 3530, 3262, 2729, 2048, 1367, 834, 566, 621, 987, 1584, 2283, 2930, 3385, 3548, 3385, 2930, 2283, 1584, 987, 621, 566, 834, 1367, 2048, 2729, 3262, 3530, 3475, 3109, 2512, 1813, 1166, 711, 548, 711, 1166, 1813, 2512, 3109, 3475, 3530, 3262, 2729, 2048, 1367, 834, 566, 621, 987, 1584, 2283, 2930, 3385, 3548, 3385, 2930, 2283, 1584, 987, 621, 566, 834, 1367, 2048, 2729, 3262, 3530, 3475, 3109, 2512, 1813, 1166, 711, 548, 711, 1166, 1813, 2512, 3109, 3475, 3530, 3262, 2729, 2048, 1367, 834, 566, 621, 987, 1584, 2283, 2930, 3385, 3548, 3385, 2930, 2283, 1584, 987, 621, 566, 834, 1367, 2048, 2729, 3262, 3530, 3475, 3109, 2512, 1813, 1166, 711, 548, 711, 1166, 1813, 2512, 3109, 3475, 3530, 3262, 2729, 2048, 1367, 834, 566, 621, 987, 1584, 2283, 2930, 3385, 3548, 3385, 2930, 2283, 1584, 987, 621, 566, 834, 1367, 2048,
        2771, 3314, 3545, 3405, 2930, 2236, 1496, 892, 575, 621, 1021, 1675, 2421, 3075, 3475, 3521, 3204, 2600, 1860, 1166, 691, 551, 782, 1325, 2048, 2771, 3314, 3545, 3405, 2930, 2236, 1496, 892, 575, 621, 1021, 1675, 2421, 3075, 3475, 3521, 3204, 2600, 1860, 1166, 691, 551, 782, 1325, 2048, 2771, 3314, 3545, 3405, 2930, 2236, 1496, 892, 575, 621, 1021, 1675, 2421, 3075, 3475, 3521, 3204, 2600, 1860, 1166, 691, 551, 782, 1325, 2048, 2771, 3314, 3545, 3405, 2930, 2236, 1496, 892, 575, 621, 1021, 1675, 2421, 3075, 3475, 3521, 3204, 2600, 1860, 1166, 691, 551, 782, 1325, 2048, 2771, 3314, 3545, 3405, 2930, 2236, 1496, 892, 575, 621, 1021, 1675, 2421, 3075, 3475, 3521, 3204, 2600, 1860, 1166, 691, 551, 782, 1325, 2048, 2771, 3314, 3545, 3405, 2930, 2236, 1496, 892, 575, 621, 1021, 1675, 2421, 3075, 3475, 3521, 3204, 2600, 1860, 1166, 691, 551, 782, 1325, 2048, 2771, 3314, 3545, 3405, 2930, 2236, 1496, 892, 575, 621, 1021, 1675, 2421, 3075, 3475, 3521, 3204, 2600, 1860, 1166, 691, 551, 782, 1325, 2048, 2771, 3314, 3545, 3405, 2930, 2236, 1496, 892, 575, 621, 1021, 1675, 2421, 3075, 3475, 3521, 3204, 2600, 1860, 1166, 691, 551, 782, 1325, 2048,
        2812, 3362, 3547, 3314, 2729, 1954, 1205, 691, 555, 834, 1452, 2236, 2967, 3443, 3530, 3204, 2556, 1767, 1056, 621, 584, 955, 1630, 2421, 3109, 3501, 3488, 3075, 2375, 1584, 923, 575, 637, 1092, 1813, 2600, 3233, 3536, 3425, 2930, 2189, 1409, 807, 551, 711, 1244, 2001, 2771, 3339, 3548, 3339, 2771, 2001, 1244, 711, 551, 807, 1409, 2189, 2930, 3425, 3536, 3233, 2600, 1813, 1092, 637, 575, 923, 1584, 2375, 3075, 3488, 3501, 3109, 2421, 1630, 955, 584, 621, 1056, 1767, 2556, 3204, 3530, 3443, 2967, 2236, 1452, 834, 555, 691, 1205, 1954, 2729, 3314, 3547, 3362, 2812, 2048, 1284, 734, 549, 782, 1367, 2142, 2891, 3405, 3541, 3262, 2644, 1860, 1129, 653, 566, 892, 1540, 2329, 3040, 3475, 3512, 3141, 2466, 1675, 987, 595, 608, 1021, 1721, 2512, 3173, 3521, 3459, 3004, 2283, 1496, 863, 560, 671, 1166, 1907, 2687, 3289, 3545, 3385, 2852, 2095, 1325, 757, 548, 757, 1325, 2095, 2852, 3385, 3545, 3289, 2687, 1907, 1166, 671, 560, 863, 1496, 2283, 3004, 3459, 3521, 3173, 2512, 1721, 1021, 608, 595, 987, 1675, 2466, 3141, 3512, 3475, 3040, 2329, 1540, 892, 566, 653, 1129, 1860, 2644, 3262, 3541, 3405, 2891, 2142, 1367, 782, 549, 734, 1284, 2048,
        2852, 3405, 3536, 3204, 2512, 1675, 955, 575, 653, 1166, 1954, 2771, 3362, 3545, 3262, 2600, 1767, 1021, 595, 621, 1092, 1860, 2687, 3314, 3548, 3314, 2687, 1860, 1092, 621, 595, 1021, 1767, 2600, 3262, 3545, 3362, 2771, 1954, 1166, 653, 575, 955, 1675, 2512, 3204, 3536, 3405, 2852, 2048, 1244, 691, 560, 892, 1584, 2421, 3141, 3521, 3443, 2930, 2142, 1325, 734, 551, 834, 1496, 2329, 3075, 3501, 3475, 3004, 2236, 1409, 782, 548, 782, 1409, 2236, 3004, 3475, 3501, 3075, 2329, 1496, 834, 551, 734, 1325, 2142, 2930, 3443, 3521, 3141, 2421, 1584, 892, 560, 691, 1244, 2048, 2852, 3405, 3536, 3204, 2512, 1675, 955, 575, 653, 1166, 1954, 2771, 3362, 3545, 3262, 2600, 1767, 1021, 595, 621, 1092, 1860, 2687, 3314, 3548, 3314, 2687, 1860, 1092, 621, 595, 1021, 1767, 2600, 3262, 3545, 3362, 2771, 1954, 1166, 653, 575, 955, 1675, 2512, 3204, 3536, 3405, 2852, 2048, 1244, 691, 560, 892, 1584, 2421, 3141, 3521, 3443, 2930, 2142, 1325, 734, 551, 834, 1496, 2329, 3075, 3501, 3475, 3004, 2236, 1409, 782, 548, 782, 1409, 2236, 3004, 3475, 3501, 3075, 2329, 1496, 834, 551, 734, 1325, 2142, 2930, 3443, 3521, 3141, 2421, 1584, 892, 560, 691, 1244, 2048,
        2891, 3443, 3512, 3075, 2283, 1409, 757, 551, 863, 1584, 2466, 3204, 3541, 3362, 2729, 1860, 1056, 595, 637, 1166, 2001, 2852, 3425, 3521, 3109, 2329, 1452, 782, 549, 834, 1540, 2421, 3173, 3536, 3385, 2771, 1907, 1092, 608, 621, 1129, 1954, 2812, 3405, 3530, 3141, 2375, 1496, 807, 548, 807, 1496, 2375, 3141, 3530, 3405, 2812, 1954, 1129, 621, 608, 1092, 1907, 2771, 3385, 3536, 3173, 2421, 1540, 834, 549, 782, 1452, 2329, 3109, 3521, 3425, 2852, 2001, 1166, 637, 595, 1056, 1860, 2729, 3362, 3541, 3204, 2466, 1584, 863, 551, 757, 1409, 2283, 3075, 3512, 3443, 2891, 2048, 1205, 653, 584, 1021, 1813, 2687, 3339, 3545, 3233, 2512, 1630, 892, 555, 734, 1367, 2236, 3040, 3501, 3459, 2930, 2095, 1244, 671, 575, 987, 1767, 2644, 3314, 3547, 3262, 2556, 1675, 923, 560, 711, 1325, 2189, 3004, 3488, 3475, 2967, 2142, 1284, 691, 566, 955, 1721, 2600, 3289, 3548, 3289, 2600, 1721, 955, 566, 691, 1284, 2142, 2967, 3475, 3488, 3004, 2189, 1325, 711, 560, 923, 1675, 2556, 3262, 3547, 3314, 2644, 1767, 987, 575, 671, 1244, 2095, 2930, 3459, 3501, 3040, 2236, 1367, 734, 555, 892, 1630, 2512, 3233, 3545, 3339, 2687, 1813, 1021, 584, 653, 1205, 2048,
        2930, 3475, 3475, 2930, 2048, 1166, 621, 621, 1166, 2048, 2930, 3475, 3475, 2930, 2048, 1166, 621, 621, 1166, 2048, 2930, 3475, 3475, 2930, 2048, 1166, 621, 621, 1166, 2048, 2930, 3475, 3475, 2930, 2048, 1166, 621, 621, 1166, 2048, 2930, 3475, 3475, 2930, 2048, 1166, 621, 621, 1166, 2048, 2930, 3475, 3475, 2930, 2048, 1166, 621, 621, 1166, 2048, 2930, 3475, 3475, 2930, 2048, 1166, 621, 621, 1166, 2048, 2930, 3475, 3475, 2930, 2048, 1166, 621, 621, 1166, 2048, 2930, 3475, 3475, 2930, 2048, 1166, 621, 621, 1166, 2048, 2930, 3475, 3475, 2930, 2048, 1166, 621, 621, 1166, 2048, 2930, 3475, 3475, 2930, 2048, 1166, 621, 621, 1166, 2048, 2930, 3475, 3475, 2930, 2048, 1166, 621, 621, 1166, 2048, 2930, 3475, 3475, 2930, 2048, 1166, 621, 621, 1166, 2048, 2930, 3475, 3475, 2930, 2048, 1166, 621, 621, 1166, 2048, 2930, 3475, 3475, 2930, 2048, 1166, 621, 621, 1166, 2048, 2930, 3475, 3475, 2930, 2048, 1166, 621, 621, 1166, 2048, 2930, 3475, 3475, 2930, 2048, 1166, 621, 621, 1166, 2048, 2930, 3475, 3475, 2930, 2048, 1166, 621, 621, 1166, 2048, 2930, 3475, 3475, 2930, 2048, 1166, 621, 621, 1166, 2048, 2930, 3475, 3475, 2930, 2048, 1166, 621, 621, 1166, 2048};

uint16_t DAC_COS[200 * 19] =
    { // DAC余弦缓冲区,每行 200点。第一行有2个正弦波，第三行有4个……第19行有20个
        3545, 3536, 3521, 3501, 3475, 3443, 3405, 3362, 3314, 3262, 3204, 3141, 3075, 3004, 2930, 2852, 2771, 2687, 2600, 2512, 2421, 2329, 2236, 2142, 2048, 1954, 1860, 1767, 1675, 1584, 1496, 1409, 1325, 1244, 1166, 1092, 1021, 955, 892, 834, 782, 734, 691, 653, 621, 595, 575, 560, 551, 548, 551, 560, 575, 595, 621, 653, 691, 734, 782, 834, 892, 955, 1021, 1092, 1166, 1244, 1325, 1409, 1496, 1584, 1675, 1767, 1860, 1954, 2048, 2142, 2236, 2329, 2421, 2512, 2600, 2687, 2771, 2852, 2930, 3004, 3075, 3141, 3204, 3262, 3314, 3362, 3405, 3443, 3475, 3501, 3521, 3536, 3545, 3548, 3545, 3536, 3521, 3501, 3475, 3443, 3405, 3362, 3314, 3262, 3204, 3141, 3075, 3004, 2930, 2852, 2771, 2687, 2600, 2512, 2421, 2329, 2236, 2142, 2048, 1954, 1860, 1767, 1675, 1584, 1496, 1409, 1325, 1244, 1166, 1092, 1021, 955, 892, 834, 782, 734, 691, 653, 621, 595, 575, 560, 551, 548, 551, 560, 575, 595, 621, 653, 691, 734, 782, 834, 892, 955, 1021, 1092, 1166, 1244, 1325, 1409, 1496, 1584, 1675, 1767, 1860, 1954, 2048, 2142, 2236, 2329, 2421, 2512, 2600, 2687, 2771, 2852, 2930, 3004, 3075, 3141, 3204, 3262, 3314, 3362, 3405, 3443, 3475, 3501, 3521, 3536, 3545, 3548,
        3541, 3521, 3488, 3443, 3385, 3314, 3233, 3141, 3040, 2930, 2812, 2687, 2556, 2421, 2283, 2142, 2001, 1860, 1721, 1584, 1452, 1325, 1205, 1092, 987, 892, 807, 734, 671, 621, 584, 560, 549, 551, 566, 595, 637, 691, 757, 834, 923, 1021, 1129, 1244, 1367, 1496, 1630, 1767, 1907, 2048, 2189, 2329, 2466, 2600, 2729, 2852, 2967, 3075, 3173, 3262, 3339, 3405, 3459, 3501, 3530, 3545, 3547, 3536, 3512, 3475, 3425, 3362, 3289, 3204, 3109, 3004, 2891, 2771, 2644, 2512, 2375, 2236, 2095, 1954, 1813, 1675, 1540, 1409, 1284, 1166, 1056, 955, 863, 782, 711, 653, 608, 575, 555, 548, 555, 575, 608, 653, 711, 782, 863, 955, 1056, 1166, 1284, 1409, 1540, 1675, 1813, 1954, 2095, 2236, 2375, 2512, 2644, 2771, 2891, 3004, 3109, 3204, 3289, 3362, 3425, 3475, 3512, 3536, 3547, 3545, 3530, 3501, 3459, 3405, 3339, 3262, 3173, 3075, 2967, 2852, 2729, 2600, 2466, 2329, 2189, 2048, 1907, 1767, 1630, 1496, 1367, 1244, 1129, 1021, 923, 834, 757, 691, 637, 595, 566, 551, 549, 560, 584, 621, 671, 734, 807, 892, 987, 1092, 1205, 1325, 1452, 1584, 1721, 1860, 2001, 2142, 2283, 2421, 2556, 2687, 2812, 2930, 3040, 3141, 3233, 3314, 3385, 3443, 3488, 3521, 3541, 3548,
        3536, 3501, 3443, 3362, 3262, 3141, 3004, 2852, 2687, 2512, 2329, 2142, 1954, 1767, 1584, 1409, 1244, 1092, 955, 834, 734, 653, 595, 560, 548, 560, 595, 653, 734, 834, 955, 1092, 1244, 1409, 1584, 1767, 1954, 2142, 2329, 2512, 2687, 2852, 3004, 3141, 3262, 3362, 3443, 3501, 3536, 3548, 3536, 3501, 3443, 3362, 3262, 3141, 3004, 2852, 2687, 2512, 2329, 2142, 1954, 1767, 1584, 1409, 1244, 1092, 955, 834, 734, 653, 595, 560, 548, 560, 595, 653, 734, 834, 955, 1092, 1244, 1409, 1584, 1767, 1954, 2142, 2329, 2512, 2687, 2852, 3004, 3141, 3262, 3362, 3443, 3501, 3536, 3548, 3536, 3501, 3443, 3362, 3262, 3141, 3004, 2852, 2687, 2512, 2329, 2142, 1954, 1767, 1584, 1409, 1244, 1092, 955, 834, 734, 653, 595, 560, 548, 560, 595, 653, 734, 834, 955, 1092, 1244, 1409, 1584, 1767, 1954, 2142, 2329, 2512, 2687, 2852, 3004, 3141, 3262, 3362, 3443, 3501, 3536, 3548, 3536, 3501, 3443, 3362, 3262, 3141, 3004, 2852, 2687, 2512, 2329, 2142, 1954, 1767, 1584, 1409, 1244, 1092, 955, 834, 734, 653, 595, 560, 548, 560, 595, 653, 734, 834, 955, 1092, 1244, 1409, 1584, 1767, 1954, 2142, 2329, 2512, 2687, 2852, 3004, 3141, 3262, 3362, 3443, 3501, 3536, 3548,
        3530, 3475, 3385, 3262, 3109, 2930, 2729, 2512, 2283, 2048, 1813, 1584, 1367, 1166, 987, 834, 711, 621, 566, 548, 566, 621, 711, 834, 987, 1166, 1367, 1584, 1813, 2048, 2283, 2512, 2729, 2930, 3109, 3262, 3385, 3475, 3530, 3548, 3530, 3475, 3385, 3262, 3109, 2930, 2729, 2512, 2283, 2048, 1813, 1584, 1367, 1166, 987, 834, 711, 621, 566, 548, 566, 621, 711, 834, 987, 1166, 1367, 1584, 1813, 2048, 2283, 2512, 2729, 2930, 3109, 3262, 3385, 3475, 3530, 3548, 3530, 3475, 3385, 3262, 3109, 2930, 2729, 2512, 2283, 2048, 1813, 1584, 1367, 1166, 987, 834, 711, 621, 566, 548, 566, 621, 711, 834, 987, 1166, 1367, 1584, 1813, 2048, 2283, 2512, 2729, 2930, 3109, 3262, 3385, 3475, 3530, 3548, 3530, 3475, 3385, 3262, 3109, 2930, 2729, 2512, 2283, 2048, 1813, 1584, 1367, 1166, 987, 834, 711, 621, 566, 548, 566, 621, 711, 834, 987, 1166, 1367, 1584, 1813, 2048, 2283, 2512, 2729, 2930, 3109, 3262, 3385, 3475, 3530, 3548, 3530, 3475, 3385, 3262, 3109, 2930, 2729, 2512, 2283, 2048, 1813, 1584, 1367, 1166, 987, 834, 711, 621, 566, 548, 566, 621, 711, 834, 987, 1166, 1367, 1584, 1813, 2048, 2283, 2512, 2729, 2930, 3109, 3262, 3385, 3475, 3530, 3548,
        3521, 3443, 3314, 3141, 2930, 2687, 2421, 2142, 1860, 1584, 1325, 1092, 892, 734, 621, 560, 551, 595, 691, 834, 1021, 1244, 1496, 1767, 2048, 2329, 2600, 2852, 3075, 3262, 3405, 3501, 3545, 3536, 3475, 3362, 3204, 3004, 2771, 2512, 2236, 1954, 1675, 1409, 1166, 955, 782, 653, 575, 548, 575, 653, 782, 955, 1166, 1409, 1675, 1954, 2236, 2512, 2771, 3004, 3204, 3362, 3475, 3536, 3545, 3501, 3405, 3262, 3075, 2852, 2600, 2329, 2048, 1767, 1496, 1244, 1021, 834, 691, 595, 551, 560, 621, 734, 892, 1092, 1325, 1584, 1860, 2142, 2421, 2687, 2930, 3141, 3314, 3443, 3521, 3548, 3521, 3443, 3314, 3141, 2930, 2687, 2421, 2142, 1860, 1584, 1325, 1092, 892, 734, 621, 560, 551, 595, 691, 834, 1021, 1244, 1496, 1767, 2048, 2329, 2600, 2852, 3075, 3262, 3405, 3501, 3545, 3536, 3475, 3362, 3204, 3004, 2771, 2512, 2236, 1954, 1675, 1409, 1166, 955, 782, 653, 575, 548, 575, 653, 782, 955, 1166, 1409, 1675, 1954, 2236, 2512, 2771, 3004, 3204, 3362, 3475, 3536, 3545, 3501, 3405, 3262, 3075, 2852, 2600, 2329, 2048, 1767, 1496, 1244, 1021, 834, 691, 595, 551, 560, 621, 734, 892, 1092, 1325, 1584, 1860, 2142, 2421, 2687, 2930, 3141, 3314, 3443, 3521, 3548,
        3512, 3405, 3233, 3004, 2729, 2421, 2095, 1767, 1452, 1166, 923, 734, 608, 551, 566, 653, 807, 1021, 1284, 1584, 1907, 2236, 2556, 2852, 3109, 3314, 3459, 3536, 3541, 3475, 3339, 3141, 2891, 2600, 2283, 1954, 1630, 1325, 1056, 834, 671, 575, 549, 595, 711, 892, 1129, 1409, 1721, 2048, 2375, 2687, 2967, 3204, 3385, 3501, 3547, 3521, 3425, 3262, 3040, 2771, 2466, 2142, 1813, 1496, 1205, 955, 757, 621, 555, 560, 637, 782, 987, 1244, 1540, 1860, 2189, 2512, 2812, 3075, 3289, 3443, 3530, 3545, 3488, 3362, 3173, 2930, 2644, 2329, 2001, 1675, 1367, 1092, 863, 691, 584, 548, 584, 691, 863, 1092, 1367, 1675, 2001, 2329, 2644, 2930, 3173, 3362, 3488, 3545, 3530, 3443, 3289, 3075, 2812, 2512, 2189, 1860, 1540, 1244, 987, 782, 637, 560, 555, 621, 757, 955, 1205, 1496, 1813, 2142, 2466, 2771, 3040, 3262, 3425, 3521, 3547, 3501, 3385, 3204, 2967, 2687, 2375, 2048, 1721, 1409, 1129, 892, 711, 595, 549, 575, 671, 834, 1056, 1325, 1630, 1954, 2283, 2600, 2891, 3141, 3339, 3475, 3541, 3536, 3459, 3314, 3109, 2852, 2556, 2236, 1907, 1584, 1284, 1021, 807, 653, 566, 551, 608, 734, 923, 1166, 1452, 1767, 2095, 2421, 2729, 3004, 3233, 3405, 3512, 3548,
        3501, 3362, 3141, 2852, 2512, 2142, 1767, 1409, 1092, 834, 653, 560, 560, 653, 834, 1092, 1409, 1767, 2142, 2512, 2852, 3141, 3362, 3501, 3548, 3501, 3362, 3141, 2852, 2512, 2142, 1767, 1409, 1092, 834, 653, 560, 560, 653, 834, 1092, 1409, 1767, 2142, 2512, 2852, 3141, 3362, 3501, 3548, 3501, 3362, 3141, 2852, 2512, 2142, 1767, 1409, 1092, 834, 653, 560, 560, 653, 834, 1092, 1409, 1767, 2142, 2512, 2852, 3141, 3362, 3501, 3548, 3501, 3362, 3141, 2852, 2512, 2142, 1767, 1409, 1092, 834, 653, 560, 560, 653, 834, 1092, 1409, 1767, 2142, 2512, 2852, 3141, 3362, 3501, 3548, 3501, 3362, 3141, 2852, 2512, 2142, 1767, 1409, 1092, 834, 653, 560, 560, 653, 834, 1092, 1409, 1767, 2142, 2512, 2852, 3141, 3362, 3501, 3548, 3501, 3362, 3141, 2852, 2512, 2142, 1767, 1409, 1092, 834, 653, 560, 560, 653, 834, 1092, 1409, 1767, 2142, 2512, 2852, 3141, 3362, 3501, 3548, 3501, 3362, 3141, 2852, 2512, 2142, 1767, 1409, 1092, 834, 653, 560, 560, 653, 834, 1092, 1409, 1767, 2142, 2512, 2852, 3141, 3362, 3501, 3548, 3501, 3362, 3141, 2852, 2512, 2142, 1767, 1409, 1092, 834, 653, 560, 560, 653, 834, 1092, 1409, 1767, 2142, 2512, 2852, 3141, 3362, 3501, 3548,
        3488, 3314, 3040, 2687, 2283, 1860, 1452, 1092, 807, 621, 549, 595, 757, 1021, 1367, 1767, 2189, 2600, 2967, 3262, 3459, 3545, 3512, 3362, 3109, 2771, 2375, 1954, 1540, 1166, 863, 653, 555, 575, 711, 955, 1284, 1675, 2095, 2512, 2891, 3204, 3425, 3536, 3530, 3405, 3173, 2852, 2466, 2048, 1630, 1244, 923, 691, 566, 560, 671, 892, 1205, 1584, 2001, 2421, 2812, 3141, 3385, 3521, 3541, 3443, 3233, 2930, 2556, 2142, 1721, 1325, 987, 734, 584, 551, 637, 834, 1129, 1496, 1907, 2329, 2729, 3075, 3339, 3501, 3547, 3475, 3289, 3004, 2644, 2236, 1813, 1409, 1056, 782, 608, 548, 608, 782, 1056, 1409, 1813, 2236, 2644, 3004, 3289, 3475, 3547, 3501, 3339, 3075, 2729, 2329, 1907, 1496, 1129, 834, 637, 551, 584, 734, 987, 1325, 1721, 2142, 2556, 2930, 3233, 3443, 3541, 3521, 3385, 3141, 2812, 2421, 2001, 1584, 1205, 892, 671, 560, 566, 691, 923, 1244, 1630, 2048, 2466, 2852, 3173, 3405, 3530, 3536, 3425, 3204, 2891, 2512, 2095, 1675, 1284, 955, 711, 575, 555, 653, 863, 1166, 1540, 1954, 2375, 2771, 3109, 3362, 3512, 3545, 3459, 3262, 2967, 2600, 2189, 1767, 1367, 1021, 757, 595, 549, 621, 807, 1092, 1452, 1860, 2283, 2687, 3040, 3314, 3488, 3548,
        3475, 3262, 2930, 2512, 2048, 1584, 1166, 834, 621, 548, 621, 834, 1166, 1584, 2048, 2512, 2930, 3262, 3475, 3548, 3475, 3262, 2930, 2512, 2048, 1584, 1166, 834, 621, 548, 621, 834, 1166, 1584, 2048, 2512, 2930, 3262, 3475, 3548, 3475, 3262, 2930, 2512, 2048, 1584, 1166, 834, 621, 548, 621, 834, 1166, 1584, 2048, 2512, 2930, 3262, 3475, 3548, 3475, 3262, 2930, 2512, 2048, 1584, 1166, 834, 621, 548, 621, 834, 1166, 1584, 2048, 2512, 2930, 3262, 3475, 3548, 3475, 3262, 2930, 2512, 2048, 1584, 1166, 834, 621, 548, 621, 834, 1166, 1584, 2048, 2512, 2930, 3262, 3475, 3548, 3475, 3262, 2930, 2512, 2048, 1584, 1166, 834, 621, 548, 621, 834, 1166, 1584, 2048, 2512, 2930, 3262, 3475, 3548, 3475, 3262, 2930, 2512, 2048, 1584, 1166, 834, 621, 548, 621, 834, 1166, 1584, 2048, 2512, 2930, 3262, 3475, 3548, 3475, 3262, 2930, 2512, 2048, 1584, 1166, 834, 621, 548, 621, 834, 1166, 1584, 2048, 2512, 2930, 3262, 3475, 3548, 3475, 3262, 2930, 2512, 2048, 1584, 1166, 834, 621, 548, 621, 834, 1166, 1584, 2048, 2512, 2930, 3262, 3475, 3548, 3475, 3262, 2930, 2512, 2048, 1584, 1166, 834, 621, 548, 621, 834, 1166, 1584, 2048, 2512, 2930, 3262, 3475, 3548,
        3459, 3204, 2812, 2329, 1813, 1325, 923, 653, 549, 621, 863, 1244, 1721, 2236, 2729, 3141, 3425, 3545, 3488, 3262, 2891, 2421, 1907, 1409, 987, 691, 555, 595, 807, 1166, 1630, 2142, 2644, 3075, 3385, 3536, 3512, 3314, 2967, 2512, 2001, 1496, 1056, 734, 566, 575, 757, 1092, 1540, 2048, 2556, 3004, 3339, 3521, 3530, 3362, 3040, 2600, 2095, 1584, 1129, 782, 584, 560, 711, 1021, 1452, 1954, 2466, 2930, 3289, 3501, 3541, 3405, 3109, 2687, 2189, 1675, 1205, 834, 608, 551, 671, 955, 1367, 1860, 2375, 2852, 3233, 3475, 3547, 3443, 3173, 2771, 2283, 1767, 1284, 892, 637, 548, 637, 892, 1284, 1767, 2283, 2771, 3173, 3443, 3547, 3475, 3233, 2852, 2375, 1860, 1367, 955, 671, 551, 608, 834, 1205, 1675, 2189, 2687, 3109, 3405, 3541, 3501, 3289, 2930, 2466, 1954, 1452, 1021, 711, 560, 584, 782, 1129, 1584, 2095, 2600, 3040, 3362, 3530, 3521, 3339, 3004, 2556, 2048, 1540, 1092, 757, 575, 566, 734, 1056, 1496, 2001, 2512, 2967, 3314, 3512, 3536, 3385, 3075, 2644, 2142, 1630, 1166, 807, 595, 555, 691, 987, 1409, 1907, 2421, 2891, 3262, 3488, 3545, 3425, 3141, 2729, 2236, 1721, 1244, 863, 621, 549, 653, 923, 1325, 1813, 2329, 2812, 3204, 3459, 3548,
        3443, 3141, 2687, 2142, 1584, 1092, 734, 560, 595, 834, 1244, 1767, 2329, 2852, 3262, 3501, 3536, 3362, 3004, 2512, 1954, 1409, 955, 653, 548, 653, 955, 1409, 1954, 2512, 3004, 3362, 3536, 3501, 3262, 2852, 2329, 1767, 1244, 834, 595, 560, 734, 1092, 1584, 2142, 2687, 3141, 3443, 3548, 3443, 3141, 2687, 2142, 1584, 1092, 734, 560, 595, 834, 1244, 1767, 2329, 2852, 3262, 3501, 3536, 3362, 3004, 2512, 1954, 1409, 955, 653, 548, 653, 955, 1409, 1954, 2512, 3004, 3362, 3536, 3501, 3262, 2852, 2329, 1767, 1244, 834, 595, 560, 734, 1092, 1584, 2142, 2687, 3141, 3443, 3548, 3443, 3141, 2687, 2142, 1584, 1092, 734, 560, 595, 834, 1244, 1767, 2329, 2852, 3262, 3501, 3536, 3362, 3004, 2512, 1954, 1409, 955, 653, 548, 653, 955, 1409, 1954, 2512, 3004, 3362, 3536, 3501, 3262, 2852, 2329, 1767, 1244, 834, 595, 560, 734, 1092, 1584, 2142, 2687, 3141, 3443, 3548, 3443, 3141, 2687, 2142, 1584, 1092, 734, 560, 595, 834, 1244, 1767, 2329, 2852, 3262, 3501, 3536, 3362, 3004, 2512, 1954, 1409, 955, 653, 548, 653, 955, 1409, 1954, 2512, 3004, 3362, 3536, 3501, 3262, 2852, 2329, 1767, 1244, 834, 595, 560, 734, 1092, 1584, 2142, 2687, 3141, 3443, 3548,
        3425, 3075, 2556, 1954, 1367, 892, 608, 560, 757, 1166, 1721, 2329, 2891, 3314, 3530, 3501, 3233, 2771, 2189, 1584, 1056, 691, 549, 653, 987, 1496, 2095, 2687, 3173, 3475, 3541, 3362, 2967, 2421, 1813, 1244, 807, 575, 584, 834, 1284, 1860, 2466, 3004, 3385, 3545, 3459, 3141, 2644, 2048, 1452, 955, 637, 551, 711, 1092, 1630, 2236, 2812, 3262, 3512, 3521, 3289, 2852, 2283, 1675, 1129, 734, 555, 621, 923, 1409, 2001, 2600, 3109, 3443, 3547, 3405, 3040, 2512, 1907, 1325, 863, 595, 566, 782, 1205, 1767, 2375, 2930, 3339, 3536, 3488, 3204, 2729, 2142, 1540, 1021, 671, 548, 671, 1021, 1540, 2142, 2729, 3204, 3488, 3536, 3339, 2930, 2375, 1767, 1205, 782, 566, 595, 863, 1325, 1907, 2512, 3040, 3405, 3547, 3443, 3109, 2600, 2001, 1409, 923, 621, 555, 734, 1129, 1675, 2283, 2852, 3289, 3521, 3512, 3262, 2812, 2236, 1630, 1092, 711, 551, 637, 955, 1452, 2048, 2644, 3141, 3459, 3545, 3385, 3004, 2466, 1860, 1284, 834, 584, 575, 807, 1244, 1813, 2421, 2967, 3362, 3541, 3475, 3173, 2687, 2095, 1496, 987, 653, 549, 691, 1056, 1584, 2189, 2771, 3233, 3501, 3530, 3314, 2891, 2329, 1721, 1166, 757, 560, 608, 892, 1367, 1954, 2556, 3075, 3425, 3548,
        3405, 3004, 2421, 1767, 1166, 734, 551, 653, 1021, 1584, 2236, 2852, 3314, 3536, 3475, 3141, 2600, 1954, 1325, 834, 575, 595, 892, 1409, 2048, 2687, 3204, 3501, 3521, 3262, 2771, 2142, 1496, 955, 621, 560, 782, 1244, 1860, 2512, 3075, 3443, 3545, 3362, 2930, 2329, 1675, 1092, 691, 548, 691, 1092, 1675, 2329, 2930, 3362, 3545, 3443, 3075, 2512, 1860, 1244, 782, 560, 621, 955, 1496, 2142, 2771, 3262, 3521, 3501, 3204, 2687, 2048, 1409, 892, 595, 575, 834, 1325, 1954, 2600, 3141, 3475, 3536, 3314, 2852, 2236, 1584, 1021, 653, 551, 734, 1166, 1767, 2421, 3004, 3405, 3548, 3405, 3004, 2421, 1767, 1166, 734, 551, 653, 1021, 1584, 2236, 2852, 3314, 3536, 3475, 3141, 2600, 1954, 1325, 834, 575, 595, 892, 1409, 2048, 2687, 3204, 3501, 3521, 3262, 2771, 2142, 1496, 955, 621, 560, 782, 1244, 1860, 2512, 3075, 3443, 3545, 3362, 2930, 2329, 1675, 1092, 691, 548, 691, 1092, 1675, 2329, 2930, 3362, 3545, 3443, 3075, 2512, 1860, 1244, 782, 560, 621, 955, 1496, 2142, 2771, 3262, 3521, 3501, 3204, 2687, 2048, 1409, 892, 595, 575, 834, 1325, 1954, 2600, 3141, 3475, 3536, 3314, 2852, 2236, 1584, 1021, 653, 551, 734, 1166, 1767, 2421, 3004, 3405, 3548,
        3385, 2930, 2283, 1584, 987, 621, 566, 834, 1367, 2048, 2729, 3262, 3530, 3475, 3109, 2512, 1813, 1166, 711, 548, 711, 1166, 1813, 2512, 3109, 3475, 3530, 3262, 2729, 2048, 1367, 834, 566, 621, 987, 1584, 2283, 2930, 3385, 3548, 3385, 2930, 2283, 1584, 987, 621, 566, 834, 1367, 2048, 2729, 3262, 3530, 3475, 3109, 2512, 1813, 1166, 711, 548, 711, 1166, 1813, 2512, 3109, 3475, 3530, 3262, 2729, 2048, 1367, 834, 566, 621, 987, 1584, 2283, 2930, 3385, 3548, 3385, 2930, 2283, 1584, 987, 621, 566, 834, 1367, 2048, 2729, 3262, 3530, 3475, 3109, 2512, 1813, 1166, 711, 548, 711, 1166, 1813, 2512, 3109, 3475, 3530, 3262, 2729, 2048, 1367, 834, 566, 621, 987, 1584, 2283, 2930, 3385, 3548, 3385, 2930, 2283, 1584, 987, 621, 566, 834, 1367, 2048, 2729, 3262, 3530, 3475, 3109, 2512, 1813, 1166, 711, 548, 711, 1166, 1813, 2512, 3109, 3475, 3530, 3262, 2729, 2048, 1367, 834, 566, 621, 987, 1584, 2283, 2930, 3385, 3548, 3385, 2930, 2283, 1584, 987, 621, 566, 834, 1367, 2048, 2729, 3262, 3530, 3475, 3109, 2512, 1813, 1166, 711, 548, 711, 1166, 1813, 2512, 3109, 3475, 3530, 3262, 2729, 2048, 1367, 834, 566, 621, 987, 1584, 2283, 2930, 3385, 3548,
        3362, 2852, 2142, 1409, 834, 560, 653, 1092, 1767, 2512, 3141, 3501, 3501, 3141, 2512, 1767, 1092, 653, 560, 834, 1409, 2142, 2852, 3362, 3548, 3362, 2852, 2142, 1409, 834, 560, 653, 1092, 1767, 2512, 3141, 3501, 3501, 3141, 2512, 1767, 1092, 653, 560, 834, 1409, 2142, 2852, 3362, 3548, 3362, 2852, 2142, 1409, 834, 560, 653, 1092, 1767, 2512, 3141, 3501, 3501, 3141, 2512, 1767, 1092, 653, 560, 834, 1409, 2142, 2852, 3362, 3548, 3362, 2852, 2142, 1409, 834, 560, 653, 1092, 1767, 2512, 3141, 3501, 3501, 3141, 2512, 1767, 1092, 653, 560, 834, 1409, 2142, 2852, 3362, 3548, 3362, 2852, 2142, 1409, 834, 560, 653, 1092, 1767, 2512, 3141, 3501, 3501, 3141, 2512, 1767, 1092, 653, 560, 834, 1409, 2142, 2852, 3362, 3548, 3362, 2852, 2142, 1409, 834, 560, 653, 1092, 1767, 2512, 3141, 3501, 3501, 3141, 2512, 1767, 1092, 653, 560, 834, 1409, 2142, 2852, 3362, 3548, 3362, 2852, 2142, 1409, 834, 560, 653, 1092, 1767, 2512, 3141, 3501, 3501, 3141, 2512, 1767, 1092, 653, 560, 834, 1409, 2142, 2852, 3362, 3548, 3362, 2852, 2142, 1409, 834, 560, 653, 1092, 1767, 2512, 3141, 3501, 3501, 3141, 2512, 1767, 1092, 653, 560, 834, 1409, 2142, 2852, 3362, 3548,
        3339, 2771, 2001, 1244, 711, 551, 807, 1409, 2189, 2930, 3425, 3536, 3233, 2600, 1813, 1092, 637, 575, 923, 1584, 2375, 3075, 3488, 3501, 3109, 2421, 1630, 955, 584, 621, 1056, 1767, 2556, 3204, 3530, 3443, 2967, 2236, 1452, 834, 555, 691, 1205, 1954, 2729, 3314, 3547, 3362, 2812, 2048, 1284, 734, 549, 782, 1367, 2142, 2891, 3405, 3541, 3262, 2644, 1860, 1129, 653, 566, 892, 1540, 2329, 3040, 3475, 3512, 3141, 2466, 1675, 987, 595, 608, 1021, 1721, 2512, 3173, 3521, 3459, 3004, 2283, 1496, 863, 560, 671, 1166, 1907, 2687, 3289, 3545, 3385, 2852, 2095, 1325, 757, 548, 757, 1325, 2095, 2852, 3385, 3545, 3289, 2687, 1907, 1166, 671, 560, 863, 1496, 2283, 3004, 3459, 3521, 3173, 2512, 1721, 1021, 608, 595, 987, 1675, 2466, 3141, 3512, 3475, 3040, 2329, 1540, 892, 566, 653, 1129, 1860, 2644, 3262, 3541, 3405, 2891, 2142, 1367, 782, 549, 734, 1284, 2048, 2812, 3362, 3547, 3314, 2729, 1954, 1205, 691, 555, 834, 1452, 2236, 2967, 3443, 3530, 3204, 2556, 1767, 1056, 621, 584, 955, 1630, 2421, 3109, 3501, 3488, 3075, 2375, 1584, 923, 575, 637, 1092, 1813, 2600, 3233, 3536, 3425, 2930, 2189, 1409, 807, 551, 711, 1244, 2001, 2771, 3339, 3548,
        3314, 2687, 1860, 1092, 621, 595, 1021, 1767, 2600, 3262, 3545, 3362, 2771, 1954, 1166, 653, 575, 955, 1675, 2512, 3204, 3536, 3405, 2852, 2048, 1244, 691, 560, 892, 1584, 2421, 3141, 3521, 3443, 2930, 2142, 1325, 734, 551, 834, 1496, 2329, 3075, 3501, 3475, 3004, 2236, 1409, 782, 548, 782, 1409, 2236, 3004, 3475, 3501, 3075, 2329, 1496, 834, 551, 734, 1325, 2142, 2930, 3443, 3521, 3141, 2421, 1584, 892, 560, 691, 1244, 2048, 2852, 3405, 3536, 3204, 2512, 1675, 955, 575, 653, 1166, 1954, 2771, 3362, 3545, 3262, 2600, 1767, 1021, 595, 621, 1092, 1860, 2687, 3314, 3548, 3314, 2687, 1860, 1092, 621, 595, 1021, 1767, 2600, 3262, 3545, 3362, 2771, 1954, 1166, 653, 575, 955, 1675, 2512, 3204, 3536, 3405, 2852, 2048, 1244, 691, 560, 892, 1584, 2421, 3141, 3521, 3443, 2930, 2142, 1325, 734, 551, 834, 1496, 2329, 3075, 3501, 3475, 3004, 2236, 1409, 782, 548, 782, 1409, 2236, 3004, 3475, 3501, 3075, 2329, 1496, 834, 551, 734, 1325, 2142, 2930, 3443, 3521, 3141, 2421, 1584, 892, 560, 691, 1244, 2048, 2852, 3405, 3536, 3204, 2512, 1675, 955, 575, 653, 1166, 1954, 2771, 3362, 3545, 3262, 2600, 1767, 1021, 595, 621, 1092, 1860, 2687, 3314, 3548,
        3289, 2600, 1721, 955, 566, 691, 1284, 2142, 2967, 3475, 3488, 3004, 2189, 1325, 711, 560, 923, 1675, 2556, 3262, 3547, 3314, 2644, 1767, 987, 575, 671, 1244, 2095, 2930, 3459, 3501, 3040, 2236, 1367, 734, 555, 892, 1630, 2512, 3233, 3545, 3339, 2687, 1813, 1021, 584, 653, 1205, 2048, 2891, 3443, 3512, 3075, 2283, 1409, 757, 551, 863, 1584, 2466, 3204, 3541, 3362, 2729, 1860, 1056, 595, 637, 1166, 2001, 2852, 3425, 3521, 3109, 2329, 1452, 782, 549, 834, 1540, 2421, 3173, 3536, 3385, 2771, 1907, 1092, 608, 621, 1129, 1954, 2812, 3405, 3530, 3141, 2375, 1496, 807, 548, 807, 1496, 2375, 3141, 3530, 3405, 2812, 1954, 1129, 621, 608, 1092, 1907, 2771, 3385, 3536, 3173, 2421, 1540, 834, 549, 782, 1452, 2329, 3109, 3521, 3425, 2852, 2001, 1166, 637, 595, 1056, 1860, 2729, 3362, 3541, 3204, 2466, 1584, 863, 551, 757, 1409, 2283, 3075, 3512, 3443, 2891, 2048, 1205, 653, 584, 1021, 1813, 2687, 3339, 3545, 3233, 2512, 1630, 892, 555, 734, 1367, 2236, 3040, 3501, 3459, 2930, 2095, 1244, 671, 575, 987, 1767, 2644, 3314, 3547, 3262, 2556, 1675, 923, 560, 711, 1325, 2189, 3004, 3488, 3475, 2967, 2142, 1284, 691, 566, 955, 1721, 2600, 3289, 3548,
        3262, 2512, 1584, 834, 548, 834, 1584, 2512, 3262, 3548, 3262, 2512, 1584, 834, 548, 834, 1584, 2512, 3262, 3548, 3262, 2512, 1584, 834, 548, 834, 1584, 2512, 3262, 3548, 3262, 2512, 1584, 834, 548, 834, 1584, 2512, 3262, 3548, 3262, 2512, 1584, 834, 548, 834, 1584, 2512, 3262, 3548, 3262, 2512, 1584, 834, 548, 834, 1584, 2512, 3262, 3548, 3262, 2512, 1584, 834, 548, 834, 1584, 2512, 3262, 3548, 3262, 2512, 1584, 834, 548, 834, 1584, 2512, 3262, 3548, 3262, 2512, 1584, 834, 548, 834, 1584, 2512, 3262, 3548, 3262, 2512, 1584, 834, 548, 834, 1584, 2512, 3262, 3548, 3262, 2512, 1584, 834, 548, 834, 1584, 2512, 3262, 3548, 3262, 2512, 1584, 834, 548, 834, 1584, 2512, 3262, 3548, 3262, 2512, 1584, 834, 548, 834, 1584, 2512, 3262, 3548, 3262, 2512, 1584, 834, 548, 834, 1584, 2512, 3262, 3548, 3262, 2512, 1584, 834, 548, 834, 1584, 2512, 3262, 3548, 3262, 2512, 1584, 834, 548, 834, 1584, 2512, 3262, 3548, 3262, 2512, 1584, 834, 548, 834, 1584, 2512, 3262, 3548, 3262, 2512, 1584, 834, 548, 834, 1584, 2512, 3262, 3548, 3262, 2512, 1584, 834, 548, 834, 1584, 2512, 3262, 3548, 3262, 2512, 1584, 834, 548, 834, 1584, 2512, 3262, 3548};

uint16_t Tri_Wave[200 * 19] =
    {
        608, 668, 728, 788, 848, 908, 968, 1028, 1088, 1148, 1208, 1268, 1328, 1388, 1448, 1508, 1568, 1628, 1688, 1748, 1808, 1868, 1928, 1988, 2048, 2108, 2168, 2228, 2288, 2348, 2408, 2468, 2528, 2588, 2648, 2708, 2768, 2828, 2888, 2948, 3008, 3068, 3128, 3188, 3248, 3308, 3368, 3428, 3488, 3548, 3488, 3428, 3368, 3308, 3248, 3188, 3128, 3068, 3008, 2948, 2888, 2828, 2768, 2708, 2648, 2588, 2528, 2468, 2408, 2348, 2288, 2228, 2168, 2108, 2048, 1988, 1928, 1868, 1808, 1748, 1688, 1628, 1568, 1508, 1448, 1388, 1328, 1268, 1208, 1148, 1088, 1028, 968, 908, 848, 788, 728, 668, 608, 548, 608, 668, 728, 788, 848, 908, 968, 1028, 1088, 1148, 1208, 1268, 1328, 1388, 1448, 1508, 1568, 1628, 1688, 1748, 1808, 1868, 1928, 1988, 2048, 2108, 2168, 2228, 2288, 2348, 2408, 2468, 2528, 2588, 2648, 2708, 2768, 2828, 2888, 2948, 3008, 3068, 3128, 3188, 3248, 3308, 3368, 3428, 3488, 3548, 3488, 3428, 3368, 3308, 3248, 3188, 3128, 3068, 3008, 2948, 2888, 2828, 2768, 2708, 2648, 2588, 2528, 2468, 2408, 2348, 2288, 2228, 2168, 2108, 2048, 1988, 1928, 1868, 1808, 1748, 1688, 1628, 1568, 1508, 1448, 1388, 1328, 1268, 1208, 1148, 1088, 1028, 968, 908, 848, 788, 728, 668, 608, 548,
        638, 728, 818, 908, 998, 1088, 1178, 1268, 1358, 1448, 1538, 1628, 1718, 1808, 1898, 1988, 2078, 2168, 2258, 2348, 2438, 2528, 2618, 2708, 2798, 2888, 2978, 3068, 3158, 3248, 3338, 3428, 3518, 3488, 3398, 3308, 3218, 3128, 3038, 2948, 2858, 2768, 2678, 2588, 2498, 2408, 2318, 2228, 2138, 2048, 1958, 1868, 1778, 1688, 1598, 1508, 1418, 1328, 1238, 1148, 1058, 968, 878, 788, 698, 608, 578, 668, 758, 848, 938, 1028, 1118, 1208, 1298, 1388, 1478, 1568, 1658, 1748, 1838, 1928, 2018, 2108, 2198, 2288, 2378, 2468, 2558, 2648, 2738, 2828, 2918, 3008, 3098, 3188, 3278, 3368, 3458, 3548, 3458, 3368, 3278, 3188, 3098, 3008, 2918, 2828, 2738, 2648, 2558, 2468, 2378, 2288, 2198, 2108, 2018, 1928, 1838, 1748, 1658, 1568, 1478, 1388, 1298, 1208, 1118, 1028, 938, 848, 758, 668, 578, 608, 698, 788, 878, 968, 1058, 1148, 1238, 1328, 1418, 1508, 1598, 1688, 1778, 1868, 1958, 2048, 2138, 2228, 2318, 2408, 2498, 2588, 2678, 2768, 2858, 2948, 3038, 3128, 3218, 3308, 3398, 3488, 3518, 3428, 3338, 3248, 3158, 3068, 2978, 2888, 2798, 2708, 2618, 2528, 2438, 2348, 2258, 2168, 2078, 1988, 1898, 1808, 1718, 1628, 1538, 1448, 1358, 1268, 1178, 1088, 998, 908, 818, 728, 638, 548,
        668, 788, 908, 1028, 1148, 1268, 1388, 1508, 1628, 1748, 1868, 1988, 2108, 2228, 2348, 2468, 2588, 2708, 2828, 2948, 3068, 3188, 3308, 3428, 3548, 3428, 3308, 3188, 3068, 2948, 2828, 2708, 2588, 2468, 2348, 2228, 2108, 1988, 1868, 1748, 1628, 1508, 1388, 1268, 1148, 1028, 908, 788, 668, 548, 668, 788, 908, 1028, 1148, 1268, 1388, 1508, 1628, 1748, 1868, 1988, 2108, 2228, 2348, 2468, 2588, 2708, 2828, 2948, 3068, 3188, 3308, 3428, 3548, 3428, 3308, 3188, 3068, 2948, 2828, 2708, 2588, 2468, 2348, 2228, 2108, 1988, 1868, 1748, 1628, 1508, 1388, 1268, 1148, 1028, 908, 788, 668, 548, 668, 788, 908, 1028, 1148, 1268, 1388, 1508, 1628, 1748, 1868, 1988, 2108, 2228, 2348, 2468, 2588, 2708, 2828, 2948, 3068, 3188, 3308, 3428, 3548, 3428, 3308, 3188, 3068, 2948, 2828, 2708, 2588, 2468, 2348, 2228, 2108, 1988, 1868, 1748, 1628, 1508, 1388, 1268, 1148, 1028, 908, 788, 668, 548, 668, 788, 908, 1028, 1148, 1268, 1388, 1508, 1628, 1748, 1868, 1988, 2108, 2228, 2348, 2468, 2588, 2708, 2828, 2948, 3068, 3188, 3308, 3428, 3548, 3428, 3308, 3188, 3068, 2948, 2828, 2708, 2588, 2468, 2348, 2228, 2108, 1988, 1868, 1748, 1628, 1508, 1388, 1268, 1148, 1028, 908, 788, 668, 548,
        698, 848, 998, 1148, 1298, 1448, 1598, 1748, 1898, 2048, 2198, 2348, 2498, 2648, 2798, 2948, 3098, 3248, 3398, 3548, 3398, 3248, 3098, 2948, 2798, 2648, 2498, 2348, 2198, 2048, 1898, 1748, 1598, 1448, 1298, 1148, 998, 848, 698, 548, 698, 848, 998, 1148, 1298, 1448, 1598, 1748, 1898, 2048, 2198, 2348, 2498, 2648, 2798, 2948, 3098, 3248, 3398, 3548, 3398, 3248, 3098, 2948, 2798, 2648, 2498, 2348, 2198, 2048, 1898, 1748, 1598, 1448, 1298, 1148, 998, 848, 698, 548, 698, 848, 998, 1148, 1298, 1448, 1598, 1748, 1898, 2048, 2198, 2348, 2498, 2648, 2798, 2948, 3098, 3248, 3398, 3548, 3398, 3248, 3098, 2948, 2798, 2648, 2498, 2348, 2198, 2048, 1898, 1748, 1598, 1448, 1298, 1148, 998, 848, 698, 548, 698, 848, 998, 1148, 1298, 1448, 1598, 1748, 1898, 2048, 2198, 2348, 2498, 2648, 2798, 2948, 3098, 3248, 3398, 3548, 3398, 3248, 3098, 2948, 2798, 2648, 2498, 2348, 2198, 2048, 1898, 1748, 1598, 1448, 1298, 1148, 998, 848, 698, 548, 698, 848, 998, 1148, 1298, 1448, 1598, 1748, 1898, 2048, 2198, 2348, 2498, 2648, 2798, 2948, 3098, 3248, 3398, 3548, 3398, 3248, 3098, 2948, 2798, 2648, 2498, 2348, 2198, 2048, 1898, 1748, 1598, 1448, 1298, 1148, 998, 848, 698, 548,
        728, 908, 1088, 1268, 1448, 1628, 1808, 1988, 2168, 2348, 2528, 2708, 2888, 3068, 3248, 3428, 3488, 3308, 3128, 2948, 2768, 2588, 2408, 2228, 2048, 1868, 1688, 1508, 1328, 1148, 968, 788, 608, 668, 848, 1028, 1208, 1388, 1568, 1748, 1928, 2108, 2288, 2468, 2648, 2828, 3008, 3188, 3368, 3548, 3368, 3188, 3008, 2828, 2648, 2468, 2288, 2108, 1928, 1748, 1568, 1388, 1208, 1028, 848, 668, 608, 788, 968, 1148, 1328, 1508, 1688, 1868, 2048, 2228, 2408, 2588, 2768, 2948, 3128, 3308, 3488, 3428, 3248, 3068, 2888, 2708, 2528, 2348, 2168, 1988, 1808, 1628, 1448, 1268, 1088, 908, 728, 548, 728, 908, 1088, 1268, 1448, 1628, 1808, 1988, 2168, 2348, 2528, 2708, 2888, 3068, 3248, 3428, 3488, 3308, 3128, 2948, 2768, 2588, 2408, 2228, 2048, 1868, 1688, 1508, 1328, 1148, 968, 788, 608, 668, 848, 1028, 1208, 1388, 1568, 1748, 1928, 2108, 2288, 2468, 2648, 2828, 3008, 3188, 3368, 3548, 3368, 3188, 3008, 2828, 2648, 2468, 2288, 2108, 1928, 1748, 1568, 1388, 1208, 1028, 848, 668, 608, 788, 968, 1148, 1328, 1508, 1688, 1868, 2048, 2228, 2408, 2588, 2768, 2948, 3128, 3308, 3488, 3428, 3248, 3068, 2888, 2708, 2528, 2348, 2168, 1988, 1808, 1628, 1448, 1268, 1088, 908, 728, 548,
        758, 968, 1178, 1388, 1598, 1808, 2018, 2228, 2438, 2648, 2858, 3068, 3278, 3488, 3398, 3188, 2978, 2768, 2558, 2348, 2138, 1928, 1718, 1508, 1298, 1088, 878, 668, 638, 848, 1058, 1268, 1478, 1688, 1898, 2108, 2318, 2528, 2738, 2948, 3158, 3368, 3518, 3308, 3098, 2888, 2678, 2468, 2258, 2048, 1838, 1628, 1418, 1208, 998, 788, 578, 728, 938, 1148, 1358, 1568, 1778, 1988, 2198, 2408, 2618, 2828, 3038, 3248, 3458, 3428, 3218, 3008, 2798, 2588, 2378, 2168, 1958, 1748, 1538, 1328, 1118, 908, 698, 608, 818, 1028, 1238, 1448, 1658, 1868, 2078, 2288, 2498, 2708, 2918, 3128, 3338, 3548, 3338, 3128, 2918, 2708, 2498, 2288, 2078, 1868, 1658, 1448, 1238, 1028, 818, 608, 698, 908, 1118, 1328, 1538, 1748, 1958, 2168, 2378, 2588, 2798, 3008, 3218, 3428, 3458, 3248, 3038, 2828, 2618, 2408, 2198, 1988, 1778, 1568, 1358, 1148, 938, 728, 578, 788, 998, 1208, 1418, 1628, 1838, 2048, 2258, 2468, 2678, 2888, 3098, 3308, 3518, 3368, 3158, 2948, 2738, 2528, 2318, 2108, 1898, 1688, 1478, 1268, 1058, 848, 638, 668, 878, 1088, 1298, 1508, 1718, 1928, 2138, 2348, 2558, 2768, 2978, 3188, 3398, 3488, 3278, 3068, 2858, 2648, 2438, 2228, 2018, 1808, 1598, 1388, 1178, 968, 758, 548,
        788, 1028, 1268, 1508, 1748, 1988, 2228, 2468, 2708, 2948, 3188, 3428, 3428, 3188, 2948, 2708, 2468, 2228, 1988, 1748, 1508, 1268, 1028, 788, 548, 788, 1028, 1268, 1508, 1748, 1988, 2228, 2468, 2708, 2948, 3188, 3428, 3428, 3188, 2948, 2708, 2468, 2228, 1988, 1748, 1508, 1268, 1028, 788, 548, 788, 1028, 1268, 1508, 1748, 1988, 2228, 2468, 2708, 2948, 3188, 3428, 3428, 3188, 2948, 2708, 2468, 2228, 1988, 1748, 1508, 1268, 1028, 788, 548, 788, 1028, 1268, 1508, 1748, 1988, 2228, 2468, 2708, 2948, 3188, 3428, 3428, 3188, 2948, 2708, 2468, 2228, 1988, 1748, 1508, 1268, 1028, 788, 548, 788, 1028, 1268, 1508, 1748, 1988, 2228, 2468, 2708, 2948, 3188, 3428, 3428, 3188, 2948, 2708, 2468, 2228, 1988, 1748, 1508, 1268, 1028, 788, 548, 788, 1028, 1268, 1508, 1748, 1988, 2228, 2468, 2708, 2948, 3188, 3428, 3428, 3188, 2948, 2708, 2468, 2228, 1988, 1748, 1508, 1268, 1028, 788, 548, 788, 1028, 1268, 1508, 1748, 1988, 2228, 2468, 2708, 2948, 3188, 3428, 3428, 3188, 2948, 2708, 2468, 2228, 1988, 1748, 1508, 1268, 1028, 788, 548, 788, 1028, 1268, 1508, 1748, 1988, 2228, 2468, 2708, 2948, 3188, 3428, 3428, 3188, 2948, 2708, 2468, 2228, 1988, 1748, 1508, 1268, 1028, 788, 548,
        818, 1088, 1358, 1628, 1898, 2168, 2438, 2708, 2978, 3248, 3518, 3308, 3038, 2768, 2498, 2228, 1958, 1688, 1418, 1148, 878, 608, 758, 1028, 1298, 1568, 1838, 2108, 2378, 2648, 2918, 3188, 3458, 3368, 3098, 2828, 2558, 2288, 2018, 1748, 1478, 1208, 938, 668, 698, 968, 1238, 1508, 1778, 2048, 2318, 2588, 2858, 3128, 3398, 3428, 3158, 2888, 2618, 2348, 2078, 1808, 1538, 1268, 998, 728, 638, 908, 1178, 1448, 1718, 1988, 2258, 2528, 2798, 3068, 3338, 3488, 3218, 2948, 2678, 2408, 2138, 1868, 1598, 1328, 1058, 788, 578, 848, 1118, 1388, 1658, 1928, 2198, 2468, 2738, 3008, 3278, 3548, 3278, 3008, 2738, 2468, 2198, 1928, 1658, 1388, 1118, 848, 578, 788, 1058, 1328, 1598, 1868, 2138, 2408, 2678, 2948, 3218, 3488, 3338, 3068, 2798, 2528, 2258, 1988, 1718, 1448, 1178, 908, 638, 728, 998, 1268, 1538, 1808, 2078, 2348, 2618, 2888, 3158, 3428, 3398, 3128, 2858, 2588, 2318, 2048, 1778, 1508, 1238, 968, 698, 668, 938, 1208, 1478, 1748, 2018, 2288, 2558, 2828, 3098, 3368, 3458, 3188, 2918, 2648, 2378, 2108, 1838, 1568, 1298, 1028, 758, 608, 878, 1148, 1418, 1688, 1958, 2228, 2498, 2768, 3038, 3308, 3518, 3248, 2978, 2708, 2438, 2168, 1898, 1628, 1358, 1088, 818, 548,
        848, 1148, 1448, 1748, 2048, 2348, 2648, 2948, 3248, 3548, 3248, 2948, 2648, 2348, 2048, 1748, 1448, 1148, 848, 548, 848, 1148, 1448, 1748, 2048, 2348, 2648, 2948, 3248, 3548, 3248, 2948, 2648, 2348, 2048, 1748, 1448, 1148, 848, 548, 848, 1148, 1448, 1748, 2048, 2348, 2648, 2948, 3248, 3548, 3248, 2948, 2648, 2348, 2048, 1748, 1448, 1148, 848, 548, 848, 1148, 1448, 1748, 2048, 2348, 2648, 2948, 3248, 3548, 3248, 2948, 2648, 2348, 2048, 1748, 1448, 1148, 848, 548, 848, 1148, 1448, 1748, 2048, 2348, 2648, 2948, 3248, 3548, 3248, 2948, 2648, 2348, 2048, 1748, 1448, 1148, 848, 548, 848, 1148, 1448, 1748, 2048, 2348, 2648, 2948, 3248, 3548, 3248, 2948, 2648, 2348, 2048, 1748, 1448, 1148, 848, 548, 848, 1148, 1448, 1748, 2048, 2348, 2648, 2948, 3248, 3548, 3248, 2948, 2648, 2348, 2048, 1748, 1448, 1148, 848, 548, 848, 1148, 1448, 1748, 2048, 2348, 2648, 2948, 3248, 3548, 3248, 2948, 2648, 2348, 2048, 1748, 1448, 1148, 848, 548, 848, 1148, 1448, 1748, 2048, 2348, 2648, 2948, 3248, 3548, 3248, 2948, 2648, 2348, 2048, 1748, 1448, 1148, 848, 548, 848, 1148, 1448, 1748, 2048, 2348, 2648, 2948, 3248, 3548, 3248, 2948, 2648, 2348, 2048, 1748, 1448, 1148, 848, 548,
        878, 1208, 1538, 1868, 2198, 2528, 2858, 3188, 3518, 3248, 2918, 2588, 2258, 1928, 1598, 1268, 938, 608, 818, 1148, 1478, 1808, 2138, 2468, 2798, 3128, 3458, 3308, 2978, 2648, 2318, 1988, 1658, 1328, 998, 668, 758, 1088, 1418, 1748, 2078, 2408, 2738, 3068, 3398, 3368, 3038, 2708, 2378, 2048, 1718, 1388, 1058, 728, 698, 1028, 1358, 1688, 2018, 2348, 2678, 3008, 3338, 3428, 3098, 2768, 2438, 2108, 1778, 1448, 1118, 788, 638, 968, 1298, 1628, 1958, 2288, 2618, 2948, 3278, 3488, 3158, 2828, 2498, 2168, 1838, 1508, 1178, 848, 578, 908, 1238, 1568, 1898, 2228, 2558, 2888, 3218, 3548, 3218, 2888, 2558, 2228, 1898, 1568, 1238, 908, 578, 848, 1178, 1508, 1838, 2168, 2498, 2828, 3158, 3488, 3278, 2948, 2618, 2288, 1958, 1628, 1298, 968, 638, 788, 1118, 1448, 1778, 2108, 2438, 2768, 3098, 3428, 3338, 3008, 2678, 2348, 2018, 1688, 1358, 1028, 698, 728, 1058, 1388, 1718, 2048, 2378, 2708, 3038, 3368, 3398, 3068, 2738, 2408, 2078, 1748, 1418, 1088, 758, 668, 998, 1328, 1658, 1988, 2318, 2648, 2978, 3308, 3458, 3128, 2798, 2468, 2138, 1808, 1478, 1148, 818, 608, 938, 1268, 1598, 1928, 2258, 2588, 2918, 3248, 3518, 3188, 2858, 2528, 2198, 1868, 1538, 1208, 878, 548,
        908, 1268, 1628, 1988, 2348, 2708, 3068, 3428, 3308, 2948, 2588, 2228, 1868, 1508, 1148, 788, 668, 1028, 1388, 1748, 2108, 2468, 2828, 3188, 3548, 3188, 2828, 2468, 2108, 1748, 1388, 1028, 668, 788, 1148, 1508, 1868, 2228, 2588, 2948, 3308, 3428, 3068, 2708, 2348, 1988, 1628, 1268, 908, 548, 908, 1268, 1628, 1988, 2348, 2708, 3068, 3428, 3308, 2948, 2588, 2228, 1868, 1508, 1148, 788, 668, 1028, 1388, 1748, 2108, 2468, 2828, 3188, 3548, 3188, 2828, 2468, 2108, 1748, 1388, 1028, 668, 788, 1148, 1508, 1868, 2228, 2588, 2948, 3308, 3428, 3068, 2708, 2348, 1988, 1628, 1268, 908, 548, 908, 1268, 1628, 1988, 2348, 2708, 3068, 3428, 3308, 2948, 2588, 2228, 1868, 1508, 1148, 788, 668, 1028, 1388, 1748, 2108, 2468, 2828, 3188, 3548, 3188, 2828, 2468, 2108, 1748, 1388, 1028, 668, 788, 1148, 1508, 1868, 2228, 2588, 2948, 3308, 3428, 3068, 2708, 2348, 1988, 1628, 1268, 908, 548, 908, 1268, 1628, 1988, 2348, 2708, 3068, 3428, 3308, 2948, 2588, 2228, 1868, 1508, 1148, 788, 668, 1028, 1388, 1748, 2108, 2468, 2828, 3188, 3548, 3188, 2828, 2468, 2108, 1748, 1388, 1028, 668, 788, 1148, 1508, 1868, 2228, 2588, 2948, 3308, 3428, 3068, 2708, 2348, 1988, 1628, 1268, 908, 548,
        938, 1328, 1718, 2108, 2498, 2888, 3278, 3428, 3038, 2648, 2258, 1868, 1478, 1088, 698, 788, 1178, 1568, 1958, 2348, 2738, 3128, 3518, 3188, 2798, 2408, 2018, 1628, 1238, 848, 638, 1028, 1418, 1808, 2198, 2588, 2978, 3368, 3338, 2948, 2558, 2168, 1778, 1388, 998, 608, 878, 1268, 1658, 2048, 2438, 2828, 3218, 3488, 3098, 2708, 2318, 1928, 1538, 1148, 758, 728, 1118, 1508, 1898, 2288, 2678, 3068, 3458, 3248, 2858, 2468, 2078, 1688, 1298, 908, 578, 968, 1358, 1748, 2138, 2528, 2918, 3308, 3398, 3008, 2618, 2228, 1838, 1448, 1058, 668, 818, 1208, 1598, 1988, 2378, 2768, 3158, 3548, 3158, 2768, 2378, 1988, 1598, 1208, 818, 668, 1058, 1448, 1838, 2228, 2618, 3008, 3398, 3308, 2918, 2528, 2138, 1748, 1358, 968, 578, 908, 1298, 1688, 2078, 2468, 2858, 3248, 3458, 3068, 2678, 2288, 1898, 1508, 1118, 728, 758, 1148, 1538, 1928, 2318, 2708, 3098, 3488, 3218, 2828, 2438, 2048, 1658, 1268, 878, 608, 998, 1388, 1778, 2168, 2558, 2948, 3338, 3368, 2978, 2588, 2198, 1808, 1418, 1028, 638, 848, 1238, 1628, 2018, 2408, 2798, 3188, 3518, 3128, 2738, 2348, 1958, 1568, 1178, 788, 698, 1088, 1478, 1868, 2258, 2648, 3038, 3428, 3278, 2888, 2498, 2108, 1718, 1328, 938, 548,
        968, 1388, 1808, 2228, 2648, 3068, 3488, 3188, 2768, 2348, 1928, 1508, 1088, 668, 848, 1268, 1688, 2108, 2528, 2948, 3368, 3308, 2888, 2468, 2048, 1628, 1208, 788, 728, 1148, 1568, 1988, 2408, 2828, 3248, 3428, 3008, 2588, 2168, 1748, 1328, 908, 608, 1028, 1448, 1868, 2288, 2708, 3128, 3548, 3128, 2708, 2288, 1868, 1448, 1028, 608, 908, 1328, 1748, 2168, 2588, 3008, 3428, 3248, 2828, 2408, 1988, 1568, 1148, 728, 788, 1208, 1628, 2048, 2468, 2888, 3308, 3368, 2948, 2528, 2108, 1688, 1268, 848, 668, 1088, 1508, 1928, 2348, 2768, 3188, 3488, 3068, 2648, 2228, 1808, 1388, 968, 548, 968, 1388, 1808, 2228, 2648, 3068, 3488, 3188, 2768, 2348, 1928, 1508, 1088, 668, 848, 1268, 1688, 2108, 2528, 2948, 3368, 3308, 2888, 2468, 2048, 1628, 1208, 788, 728, 1148, 1568, 1988, 2408, 2828, 3248, 3428, 3008, 2588, 2168, 1748, 1328, 908, 608, 1028, 1448, 1868, 2288, 2708, 3128, 3548, 3128, 2708, 2288, 1868, 1448, 1028, 608, 908, 1328, 1748, 2168, 2588, 3008, 3428, 3248, 2828, 2408, 1988, 1568, 1148, 728, 788, 1208, 1628, 2048, 2468, 2888, 3308, 3368, 2948, 2528, 2108, 1688, 1268, 848, 668, 1088, 1508, 1928, 2348, 2768, 3188, 3488, 3068, 2648, 2228, 1808, 1388, 968, 548,
        998, 1448, 1898, 2348, 2798, 3248, 3398, 2948, 2498, 2048, 1598, 1148, 698, 848, 1298, 1748, 2198, 2648, 3098, 3548, 3098, 2648, 2198, 1748, 1298, 848, 698, 1148, 1598, 2048, 2498, 2948, 3398, 3248, 2798, 2348, 1898, 1448, 998, 548, 998, 1448, 1898, 2348, 2798, 3248, 3398, 2948, 2498, 2048, 1598, 1148, 698, 848, 1298, 1748, 2198, 2648, 3098, 3548, 3098, 2648, 2198, 1748, 1298, 848, 698, 1148, 1598, 2048, 2498, 2948, 3398, 3248, 2798, 2348, 1898, 1448, 998, 548, 998, 1448, 1898, 2348, 2798, 3248, 3398, 2948, 2498, 2048, 1598, 1148, 698, 848, 1298, 1748, 2198, 2648, 3098, 3548, 3098, 2648, 2198, 1748, 1298, 848, 698, 1148, 1598, 2048, 2498, 2948, 3398, 3248, 2798, 2348, 1898, 1448, 998, 548, 998, 1448, 1898, 2348, 2798, 3248, 3398, 2948, 2498, 2048, 1598, 1148, 698, 848, 1298, 1748, 2198, 2648, 3098, 3548, 3098, 2648, 2198, 1748, 1298, 848, 698, 1148, 1598, 2048, 2498, 2948, 3398, 3248, 2798, 2348, 1898, 1448, 998, 548, 998, 1448, 1898, 2348, 2798, 3248, 3398, 2948, 2498, 2048, 1598, 1148, 698, 848, 1298, 1748, 2198, 2648, 3098, 3548, 3098, 2648, 2198, 1748, 1298, 848, 698, 1148, 1598, 2048, 2498, 2948, 3398, 3248, 2798, 2348, 1898, 1448, 998, 548,
        1028, 1508, 1988, 2468, 2948, 3428, 3188, 2708, 2228, 1748, 1268, 788, 788, 1268, 1748, 2228, 2708, 3188, 3428, 2948, 2468, 1988, 1508, 1028, 548, 1028, 1508, 1988, 2468, 2948, 3428, 3188, 2708, 2228, 1748, 1268, 788, 788, 1268, 1748, 2228, 2708, 3188, 3428, 2948, 2468, 1988, 1508, 1028, 548, 1028, 1508, 1988, 2468, 2948, 3428, 3188, 2708, 2228, 1748, 1268, 788, 788, 1268, 1748, 2228, 2708, 3188, 3428, 2948, 2468, 1988, 1508, 1028, 548, 1028, 1508, 1988, 2468, 2948, 3428, 3188, 2708, 2228, 1748, 1268, 788, 788, 1268, 1748, 2228, 2708, 3188, 3428, 2948, 2468, 1988, 1508, 1028, 548, 1028, 1508, 1988, 2468, 2948, 3428, 3188, 2708, 2228, 1748, 1268, 788, 788, 1268, 1748, 2228, 2708, 3188, 3428, 2948, 2468, 1988, 1508, 1028, 548, 1028, 1508, 1988, 2468, 2948, 3428, 3188, 2708, 2228, 1748, 1268, 788, 788, 1268, 1748, 2228, 2708, 3188, 3428, 2948, 2468, 1988, 1508, 1028, 548, 1028, 1508, 1988, 2468, 2948, 3428, 3188, 2708, 2228, 1748, 1268, 788, 788, 1268, 1748, 2228, 2708, 3188, 3428, 2948, 2468, 1988, 1508, 1028, 548, 1028, 1508, 1988, 2468, 2948, 3428, 3188, 2708, 2228, 1748, 1268, 788, 788, 1268, 1748, 2228, 2708, 3188, 3428, 2948, 2468, 1988, 1508, 1028, 548,
        1058, 1568, 2078, 2588, 3098, 3488, 2978, 2468, 1958, 1448, 938, 668, 1178, 1688, 2198, 2708, 3218, 3368, 2858, 2348, 1838, 1328, 818, 788, 1298, 1808, 2318, 2828, 3338, 3248, 2738, 2228, 1718, 1208, 698, 908, 1418, 1928, 2438, 2948, 3458, 3128, 2618, 2108, 1598, 1088, 578, 1028, 1538, 2048, 2558, 3068, 3518, 3008, 2498, 1988, 1478, 968, 638, 1148, 1658, 2168, 2678, 3188, 3398, 2888, 2378, 1868, 1358, 848, 758, 1268, 1778, 2288, 2798, 3308, 3278, 2768, 2258, 1748, 1238, 728, 878, 1388, 1898, 2408, 2918, 3428, 3158, 2648, 2138, 1628, 1118, 608, 998, 1508, 2018, 2528, 3038, 3548, 3038, 2528, 2018, 1508, 998, 608, 1118, 1628, 2138, 2648, 3158, 3428, 2918, 2408, 1898, 1388, 878, 728, 1238, 1748, 2258, 2768, 3278, 3308, 2798, 2288, 1778, 1268, 758, 848, 1358, 1868, 2378, 2888, 3398, 3188, 2678, 2168, 1658, 1148, 638, 968, 1478, 1988, 2498, 3008, 3518, 3068, 2558, 2048, 1538, 1028, 578, 1088, 1598, 2108, 2618, 3128, 3458, 2948, 2438, 1928, 1418, 908, 698, 1208, 1718, 2228, 2738, 3248, 3338, 2828, 2318, 1808, 1298, 788, 818, 1328, 1838, 2348, 2858, 3368, 3218, 2708, 2198, 1688, 1178, 668, 938, 1448, 1958, 2468, 2978, 3488, 3098, 2588, 2078, 1568, 1058, 548,
        1088, 1628, 2168, 2708, 3248, 3308, 2768, 2228, 1688, 1148, 608, 1028, 1568, 2108, 2648, 3188, 3368, 2828, 2288, 1748, 1208, 668, 968, 1508, 2048, 2588, 3128, 3428, 2888, 2348, 1808, 1268, 728, 908, 1448, 1988, 2528, 3068, 3488, 2948, 2408, 1868, 1328, 788, 848, 1388, 1928, 2468, 3008, 3548, 3008, 2468, 1928, 1388, 848, 788, 1328, 1868, 2408, 2948, 3488, 3068, 2528, 1988, 1448, 908, 728, 1268, 1808, 2348, 2888, 3428, 3128, 2588, 2048, 1508, 968, 668, 1208, 1748, 2288, 2828, 3368, 3188, 2648, 2108, 1568, 1028, 608, 1148, 1688, 2228, 2768, 3308, 3248, 2708, 2168, 1628, 1088, 548, 1088, 1628, 2168, 2708, 3248, 3308, 2768, 2228, 1688, 1148, 608, 1028, 1568, 2108, 2648, 3188, 3368, 2828, 2288, 1748, 1208, 668, 968, 1508, 2048, 2588, 3128, 3428, 2888, 2348, 1808, 1268, 728, 908, 1448, 1988, 2528, 3068, 3488, 2948, 2408, 1868, 1328, 788, 848, 1388, 1928, 2468, 3008, 3548, 3008, 2468, 1928, 1388, 848, 788, 1328, 1868, 2408, 2948, 3488, 3068, 2528, 1988, 1448, 908, 728, 1268, 1808, 2348, 2888, 3428, 3128, 2588, 2048, 1508, 968, 668, 1208, 1748, 2288, 2828, 3368, 3188, 2648, 2108, 1568, 1028, 608, 1148, 1688, 2228, 2768, 3308, 3248, 2708, 2168, 1628, 1088, 548,
        1118, 1688, 2258, 2828, 3398, 3128, 2558, 1988, 1418, 848, 818, 1388, 1958, 2528, 3098, 3428, 2858, 2288, 1718, 1148, 578, 1088, 1658, 2228, 2798, 3368, 3158, 2588, 2018, 1448, 878, 788, 1358, 1928, 2498, 3068, 3458, 2888, 2318, 1748, 1178, 608, 1058, 1628, 2198, 2768, 3338, 3188, 2618, 2048, 1478, 908, 758, 1328, 1898, 2468, 3038, 3488, 2918, 2348, 1778, 1208, 638, 1028, 1598, 2168, 2738, 3308, 3218, 2648, 2078, 1508, 938, 728, 1298, 1868, 2438, 3008, 3518, 2948, 2378, 1808, 1238, 668, 998, 1568, 2138, 2708, 3278, 3248, 2678, 2108, 1538, 968, 698, 1268, 1838, 2408, 2978, 3548, 2978, 2408, 1838, 1268, 698, 968, 1538, 2108, 2678, 3248, 3278, 2708, 2138, 1568, 998, 668, 1238, 1808, 2378, 2948, 3518, 3008, 2438, 1868, 1298, 728, 938, 1508, 2078, 2648, 3218, 3308, 2738, 2168, 1598, 1028, 638, 1208, 1778, 2348, 2918, 3488, 3038, 2468, 1898, 1328, 758, 908, 1478, 2048, 2618, 3188, 3338, 2768, 2198, 1628, 1058, 608, 1178, 1748, 2318, 2888, 3458, 3068, 2498, 1928, 1358, 788, 878, 1448, 2018, 2588, 3158, 3368, 2798, 2228, 1658, 1088, 578, 1148, 1718, 2288, 2858, 3428, 3098, 2528, 1958, 1388, 818, 848, 1418, 1988, 2558, 3128, 3398, 2828, 2258, 1688, 1118, 548,
        1148, 1748, 2348, 2948, 3548, 2948, 2348, 1748, 1148, 548, 1148, 1748, 2348, 2948, 3548, 2948, 2348, 1748, 1148, 548, 1148, 1748, 2348, 2948, 3548, 2948, 2348, 1748, 1148, 548, 1148, 1748, 2348, 2948, 3548, 2948, 2348, 1748, 1148, 548, 1148, 1748, 2348, 2948, 3548, 2948, 2348, 1748, 1148, 548, 1148, 1748, 2348, 2948, 3548, 2948, 2348, 1748, 1148, 548, 1148, 1748, 2348, 2948, 3548, 2948, 2348, 1748, 1148, 548, 1148, 1748, 2348, 2948, 3548, 2948, 2348, 1748, 1148, 548, 1148, 1748, 2348, 2948, 3548, 2948, 2348, 1748, 1148, 548, 1148, 1748, 2348, 2948, 3548, 2948, 2348, 1748, 1148, 548, 1148, 1748, 2348, 2948, 3548, 2948, 2348, 1748, 1148, 548, 1148, 1748, 2348, 2948, 3548, 2948, 2348, 1748, 1148, 548, 1148, 1748, 2348, 2948, 3548, 2948, 2348, 1748, 1148, 548, 1148, 1748, 2348, 2948, 3548, 2948, 2348, 1748, 1148, 548, 1148, 1748, 2348, 2948, 3548, 2948, 2348, 1748, 1148, 548, 1148, 1748, 2348, 2948, 3548, 2948, 2348, 1748, 1148, 548, 1148, 1748, 2348, 2948, 3548, 2948, 2348, 1748, 1148, 548, 1148, 1748, 2348, 2948, 3548, 2948, 2348, 1748, 1148, 548, 1148, 1748, 2348, 2948, 3548, 2948, 2348, 1748, 1148, 548, 1148, 1748, 2348, 2948, 3548, 2948, 2348, 1748, 1148, 548};

/* USER CODE END PM */

void SystemClock_Config(void);
static void MPU_Initialize(void);
static void MPU_Config(void);
/* USER CODE BEGIN PFP */
void adc_init(void);
void cal_2fres(uint8_t *fre);
double power(double SC,double CC);
double dft_cal(uint16_t *T,uint16_t *Sin_Cos);
void cal_2types(uint8_t *fre,uint8_t *wave_type);
void get_pos_angle(void);

/* USER CODE END PFP */

int main(void)
{

  /* Enable I-Cache---------------------------------------------------------*/
  SCB_EnableICache();

  /* Enable D-Cache---------------------------------------------------------*/
  SCB_EnableDCache();

  /* MCU Configuration--------------------------------------------------------*/

  /* Reset of all peripherals, Initializes the Flash interface and the Systick. */
  HAL_Init();

  /* MPU Configuration--------------------------------------------------------*/
  MPU_Config();

  /* Configure the system clock */
  SystemClock_Config();

  /* Initialize all configured peripherals */
  MX_GPIO_Init();
  MX_DMA_Init();
  MX_TIM7_Init();
  MX_USART1_UART_Init();
  MX_ADC1_Init();
  MX_TIM15_Init();
  MX_DAC1_Init();
  MX_TIM4_Init();
  MX_TIM1_Init();
  /* USER CODE BEGIN 2 */
	printf("start\n");
  /* USER CODE END 2 */

  /* Infinite loop */
  while (1)
  {

    /* USER CODE BEGIN 3 */
restart:
			wave_type[0] = 0;
			wave_type[1] = 0;
			adc_init();
			cal_2fres(fre);
			printf("freA=%d kHz\n",fre[0]*5+10);
			printf("freB=%d kHz\n",fre[1]*5+10);
			cal_2types(fre,wave_type);
			if(wave_type[0]==0)
			{
				printf("A:sin\n");
				for(uint8_t i=0;i<200;i++)
				data_A[i]=DAC_SIN[ fre[0]*200 + i ];
			}
			else
			{
				printf("A:tri\n");
				for(uint8_t i=0;i<200;i++)
				data_A[i]=Tri_Wave[ fre[0]*200 + i ];
			}

			if(wave_type[1]==0)
			{
				printf("B:sin\n");
				for(uint8_t i=0;i<200;i++)
				data_B[i]=DAC_SIN[ fre[1]*200 + i ];
			}
			else
			{
				printf("B:tri\n");
				for(uint8_t i=0;i<200;i++)
				data_B[i]=Tri_Wave[ fre[1]*200 + i ];
			}

			HAL_DAC_Start_DMA(&hdac1,DAC_CHANNEL_1,(uint32_t *)data_A,200,DAC_ALIGN_12B_R);	//DMA
			HAL_DAC_Start_DMA(&hdac1,DAC_CHANNEL_2,(uint32_t *)data_B,200,DAC_ALIGN_12B_R);

			HAL_TIM_Base_Start(&htim1);//打开定时器1
			HAL_TIM_Base_Start(&htim4);//打开定时器4
			//不断调整相位
			while(1)
			{
				//相位自校正
				if(mode_flag == 0)
				{
					//A调相
					adc_init();
					get_pos_angle();
					HAL_DAC_Stop_DMA(&hdac1,DAC_CHANNEL_1);
					delayT_A = (24000.0 * pos_angle_A / (3.1415926 * ((double)fre[0]+2.0)) +0.5);
					TIM1->CNT = TIM1->CNT + 65535 - delayT_A;
//					HAL_DAC_Start_DMA(&hdac1,DAC_CHANNEL_1,(uint32_t *)data_A,200,DAC_ALIGN_12B_R);
//					//B调相
					adc_init();
					get_pos_angle();
					delayT_B = (24000.0 * pos_angle_B / (3.1415926 * ((double)fre[1]+2.0)) +0.5);
					TIM4->CNT = TIM4->CNT + 65535 - delayT_B;
//						printf("delayT_A = %d\n",delayT_A);
//						printf("delayT_B = %d\n",delayT_B);
				}

				//相位可调节
				else
				{
					uint32_t tao = (double)change_pha / 360 /(fre[1] * 5.0 + 10) * 240000;

					//B调相
					adc_init();
					get_pos_angle();
					delayT_B = (24000.0 * pos_angle_B / (3.1415926 * ((double)fre[1]+2.0)) +0.5);
					TIM4->CNT = TIM4->CNT + 65535 - delayT_B;

					//A在B基础上延迟tao
					TIM1->CNT = TIM1->CNT + 65535 - delayT_A - tao;

				}
					if(restart_flag == 1)
					{
						restart_flag = 0;

						goto restart;
					}
			}
  }
  /* USER CODE END 3 */
}

void SystemClock_Config(void)
{
  RCC_OscInitTypeDef RCC_OscInitStruct = {0};
  RCC_ClkInitTypeDef RCC_ClkInitStruct = {0};

  /** Supply configuration update enable
  */
  HAL_PWREx_ConfigSupply(PWR_LDO_SUPPLY);

  /** Configure the main internal regulator output voltage
  */
  __HAL_PWR_VOLTAGESCALING_CONFIG(PWR_REGULATOR_VOLTAGE_SCALE1);

  while(!__HAL_PWR_GET_FLAG(PWR_FLAG_VOSRDY)) {}

  __HAL_RCC_SYSCFG_CLK_ENABLE();
  __HAL_PWR_VOLTAGESCALING_CONFIG(PWR_REGULATOR_VOLTAGE_SCALE0);

  while(!__HAL_PWR_GET_FLAG(PWR_FLAG_VOSRDY)) {}

  /** Initializes the RCC Oscillators according to the specified parameters
  * in the RCC_OscInitTypeDef structure.
  */
  RCC_OscInitStruct.OscillatorType = RCC_OSCILLATORTYPE_HSE;
  RCC_OscInitStruct.HSEState = RCC_HSE_ON;
  RCC_OscInitStruct.PLL.PLLState = RCC_PLL_ON;
  RCC_OscInitStruct.PLL.PLLSource = RCC_PLLSOURCE_HSE;
  RCC_OscInitStruct.PLL.PLLM = 5;
  RCC_OscInitStruct.PLL.PLLN = 192;
  RCC_OscInitStruct.PLL.PLLP = 2;
  RCC_OscInitStruct.PLL.PLLQ = 2;
  RCC_OscInitStruct.PLL.PLLR = 2;
  RCC_OscInitStruct.PLL.PLLRGE = RCC_PLL1VCIRANGE_2;
  RCC_OscInitStruct.PLL.PLLVCOSEL = RCC_PLL1VCOWIDE;
  RCC_OscInitStruct.PLL.PLLFRACN = 0;
  if (HAL_RCC_OscConfig(&RCC_OscInitStruct) != HAL_OK)
  {
    Error_Handler();
  }

  /** Initializes the CPU, AHB and APB buses clocks
  */
  RCC_ClkInitStruct.ClockType = RCC_CLOCKTYPE_HCLK|RCC_CLOCKTYPE_SYSCLK
                              |RCC_CLOCKTYPE_PCLK1|RCC_CLOCKTYPE_PCLK2
                              |RCC_CLOCKTYPE_D3PCLK1|RCC_CLOCKTYPE_D1PCLK1;
  RCC_ClkInitStruct.SYSCLKSource = RCC_SYSCLKSOURCE_PLLCLK;
  RCC_ClkInitStruct.SYSCLKDivider = RCC_SYSCLK_DIV1;
  RCC_ClkInitStruct.AHBCLKDivider = RCC_HCLK_DIV2;
  RCC_ClkInitStruct.APB3CLKDivider = RCC_APB3_DIV2;
  RCC_ClkInitStruct.APB1CLKDivider = RCC_APB1_DIV2;
  RCC_ClkInitStruct.APB2CLKDivider = RCC_APB2_DIV2;
  RCC_ClkInitStruct.APB4CLKDivider = RCC_APB4_DIV2;

  if (HAL_RCC_ClockConfig(&RCC_ClkInitStruct, FLASH_LATENCY_4) != HAL_OK)
  {
    Error_Handler();
  }
}

/* USER CODE BEGIN 4 */

//dft运算中求∑
double dft_cal(uint16_t *T,uint16_t *Sin_Cos)
{
	uint16_t i;
	double result=0;
	for(i=0;i<1000;i++)
	{
		result = result + (T[i]-32768) * (Sin_Cos[i%200]-2048);
	}
	return result;
}
//求功率谱,实际求模长
double power(double SC,double CC)
{
	double power;
	power = sqrt(SC*SC+CC*CC);
	return power;
}
//信号主频率
void cal_2fres(uint8_t *fre)
{
	double SC=0;
	double CC=0;
	double Pow[19];				//功率谱
	double Pow_temp[19];	//存放排序后功率谱，最后根据索引给fre
	double temp;
	uint8_t i,j,i_temp;
	for(i=0;i<19;i++)
	{
		SC=dft_cal(adc1_data,DAC_SIN+200*i);		//第i行，200个一行
		CC=dft_cal(adc1_data,DAC_COS+200*i);
		Pow[i]=power(SC,CC);
		Pow_temp[i]=Pow[i];
	}
	//冒泡排序
	for(i=0;i<19-1;i++)
	{
		for(j=0;j<19-i-1;j++)
		{
			if(Pow_temp[j]<Pow_temp[j+1])	//降序
			{
				temp=Pow_temp[j];
				Pow_temp[j]=Pow_temp[j+1];
				Pow_temp[j+1]=temp;
			}
		}
	}
	//找最大值索引
	for(i=0;i<19;i++)
	{
		if(Pow[i]==Pow_temp[0])	//最大
			fre[0]=i;
		if(Pow[i]==Pow_temp[1])	//第二大
			fre[1]=i;
	}
	if(fre[0]>fre[1])	//低频放前面,fA<fB
	{
		i_temp=fre[0];
		fre[0]=fre[1];
		fre[1]=i_temp;
	}
}

//信号类型
void cal_2types(uint8_t *fre,uint8_t *wave_type)
{
	uint16_t fre_1_index,fre_3_index,fre_5_index;
	float temp_float;
	float pow_1,pow_3,pow_5;
	float k;
	_Bool conti;
	FFT_Init();		//FFT得到频谱，直接去找fre、3fre

	//信号一初步判断
	temp_float = (float) fre[0]*5+10;
	temp_float = temp_float/500;
	temp_float = temp_float*512;
	fre_1_index = temp_float+0.5;

	temp_float = (float) fre[0]*5+10;
	temp_float = temp_float/500;
	temp_float = temp_float*3*512;
	fre_3_index = temp_float+0.5;

	pow_1 = q1[fre_1_index-1].real + q1[fre_1_index].real + q1[fre_1_index+1].real;
	pow_3 = q1[fre_3_index-1].real + q1[fre_3_index].real + q1[fre_3_index+1].real;

	k = pow_1 / pow_3;
//	printf("k_A3= %f\n",k);
	if(k>250)
	{
		wave_type[0]=0;
	}
	else
	{
		wave_type[0]=1;
	}

	//信号二初步判断
	temp_float = (float) fre[1]*5+10;
	temp_float = temp_float/500;
	temp_float = temp_float*512;
	fre_1_index = temp_float+0.5;

	temp_float = (float) fre[1]*5+10;
	temp_float = temp_float/500;
	temp_float = temp_float*3*512;
	fre_3_index = temp_float+0.5;

	pow_1 = q1[fre_1_index-1].real + q1[fre_1_index].real + q1[fre_1_index+1].real;
	pow_3 = q1[fre_3_index-1].real + q1[fre_3_index].real + q1[fre_3_index+1].real;

	k = pow_1 / pow_3;
//	printf("k_B3= %f\n",k);
	if(k>250)
	{
		wave_type[1]=0;
	}
	else
	{
		wave_type[1]=1;
	}

	//特殊fB=3fA
	//对于B来说，他类型就有自身和三倍频判断，不会收A影响
	//对于A来说，A的三倍会被B污染，所以要根据五倍判断
	conti=((fre[0]==0)&&(fre[1]==4))||((fre[0]==1)&&(fre[1]==7))||((fre[0]==2)&&(fre[1]==10))||((fre[0]==3)&&(fre[1]==13))||((fre[0]==4)&&(fre[1]==16));
	if(conti)
	{
		temp_float = (float) fre[0]*5+10;
		temp_float = temp_float/500;
		temp_float = temp_float*512;
		fre_1_index = temp_float+0.5;

		temp_float = (float) fre[0]*5+10;
		temp_float = temp_float/500;
		temp_float = temp_float*512*5;
		fre_5_index = temp_float+0.5;

		pow_1 = q1[fre_1_index-1].real + q1[fre_1_index].real + q1[fre_1_index+1].real;
		pow_5 = q1[fre_5_index-1].real + q1[fre_5_index].real + q1[fre_5_index+1].real;

		k = pow_1 / pow_5;
		printf("k_A5= %f\n",k);
		if(k>500)		//根据实际调整
		{
			wave_type[1]=0;
			printf("A:sin \n");
		}
		else
		{
			wave_type[1]=1;
			printf("A:tri \n");
		}
	}
}

//求相位差
void get_pos_angle(void)
{
	double SC = dft_cal(adc1_data,DAC_SIN+200*fre[0]);
	double CC = dft_cal(adc1_data,DAC_COS+200*fre[0]);
	double phase = atan2(CC,SC);
	//phase在-pi到pi
	//<0，重建提前，延时即可
	//>0，重建延迟，再延时T-deltaT
	if(phase<0)
	{
		pos_angle_A = -phase;
	}
	else
	{
		pos_angle_A = 2*3.1415926 - phase;
	}
	SC = dft_cal(adc1_data,DAC_SIN+200*fre[1]);
	CC = dft_cal(adc1_data,DAC_COS+200*fre[1]);
	phase = atan2(CC,SC);
	if(phase<0)
	{
		pos_angle_B = -phase;
	}
	else
	{
		pos_angle_B = 2*3.1415926 - phase;
	}
//	printf("pos_angle_A = %f\n",pos_angle_A);
//	printf("pos_angle_B = %f\n",pos_angle_B);

}
//按键中断
void HAL_GPIO_EXTI_Callback(uint16_t GPIO_Pin)
{
	if(GPIO_Pin == KEY1_Pin)
	{
		restart_flag=1;
	}
}
//adc初始化
void adc_init(void)
{
//	printf("start_adc\n");
	MX_ADC1_Init();	//初始化调用放这里, 确保在MX_DMA_Init()初始化后靿
	HAL_Delay(100);	//有地方说这里可以等等电压稳定后再校准
	if (HAL_ADCEx_Calibration_Start(&hadc1, ADC_CALIB_OFFSET, ADC_SINGLE_ENDED) != HAL_OK)
	{
			printf("hadc1 error with HAL_ADCEx_Calibration_Start\r\n");
			Error_Handler();
	}

	if (HAL_ADC_Start_DMA(&hadc1, (uint32_t *)adc1_data, DFT_LENGTH) != HAL_OK)
	{
			printf("hadc1 error with HAL_ADC_Start_DMA\r\n");
			Error_Handler();
	}

	HAL_TIM_Base_Start(&htim15);
	while (!AdcConvEnd);
	AdcConvEnd = 0;
	HAL_ADC_DeInit(&hadc1);			//逆初始化
	HAL_TIM_Base_Stop(&htim15);
}
//ADC中断回调
void HAL_ADC_ConvCpltCallback(ADC_HandleTypeDef* hadc)
{
   if(hadc->Instance == ADC1)
	{
      //SCB_InvalidateDCache_by_Addr((uint32_t *) &adc1_data[0], ADC1_BUFFER_SIZE);
		AdcConvEnd = 1;
  }
}

/* USER CODE END 4 */

/* MPU Configuration */

void MPU_Config(void)
{
  MPU_Region_InitTypeDef MPU_InitStruct = {0};

  /* Disables the MPU */
  HAL_MPU_Disable();

  /** Initializes and configures the Region and the memory to be protected
  */
  MPU_InitStruct.Enable = MPU_REGION_ENABLE;
  MPU_InitStruct.Number = MPU_REGION_NUMBER0;
  MPU_InitStruct.BaseAddress = 0x24000000;
  MPU_InitStruct.Size = MPU_REGION_SIZE_512KB;
  MPU_InitStruct.SubRegionDisable = 0x0;
  MPU_InitStruct.TypeExtField = MPU_TEX_LEVEL1;
  MPU_InitStruct.AccessPermission = MPU_REGION_FULL_ACCESS;
  MPU_InitStruct.DisableExec = MPU_INSTRUCTION_ACCESS_ENABLE;
  MPU_InitStruct.IsShareable = MPU_ACCESS_NOT_SHAREABLE;
  MPU_InitStruct.IsCacheable = MPU_ACCESS_CACHEABLE;
  MPU_InitStruct.IsBufferable = MPU_ACCESS_BUFFERABLE;

  HAL_MPU_ConfigRegion(&MPU_InitStruct);

  /** Initializes and configures the Region and the memory to be protected
  */
  MPU_InitStruct.Number = MPU_REGION_NUMBER1;
  MPU_InitStruct.BaseAddress = 0x30000000;
  MPU_InitStruct.Size = MPU_REGION_SIZE_128KB;
  MPU_InitStruct.IsCacheable = MPU_ACCESS_NOT_CACHEABLE;
  MPU_InitStruct.IsBufferable = MPU_ACCESS_NOT_BUFFERABLE;

  HAL_MPU_ConfigRegion(&MPU_InitStruct);

  /** Initializes and configures the Region and the memory to be protected
  */
  MPU_InitStruct.Number = MPU_REGION_NUMBER2;
  MPU_InitStruct.BaseAddress = 0x30020000;

  HAL_MPU_ConfigRegion(&MPU_InitStruct);

  /** Initializes and configures the Region and the memory to be protected
  */
  MPU_InitStruct.Number = MPU_REGION_NUMBER3;
  MPU_InitStruct.BaseAddress = 0x30040000;
  MPU_InitStruct.Size = MPU_REGION_SIZE_32KB;

  HAL_MPU_ConfigRegion(&MPU_InitStruct);

  /** Initializes and configures the Region and the memory to be protected
  */
  MPU_InitStruct.Number = MPU_REGION_NUMBER4;
  MPU_InitStruct.BaseAddress = 0x38000000;
  MPU_InitStruct.Size = MPU_REGION_SIZE_64KB;

  HAL_MPU_ConfigRegion(&MPU_InitStruct);
  /* Enables the MPU */
  HAL_MPU_Enable(MPU_PRIVILEGED_DEFAULT);

}

void Error_Handler(void)
{
  __disable_irq();
  while (1)
  {
  }
}
